AUTOSAR XML (schema 4-2-2)
package /STELLANTIS/EPT/ASWCs
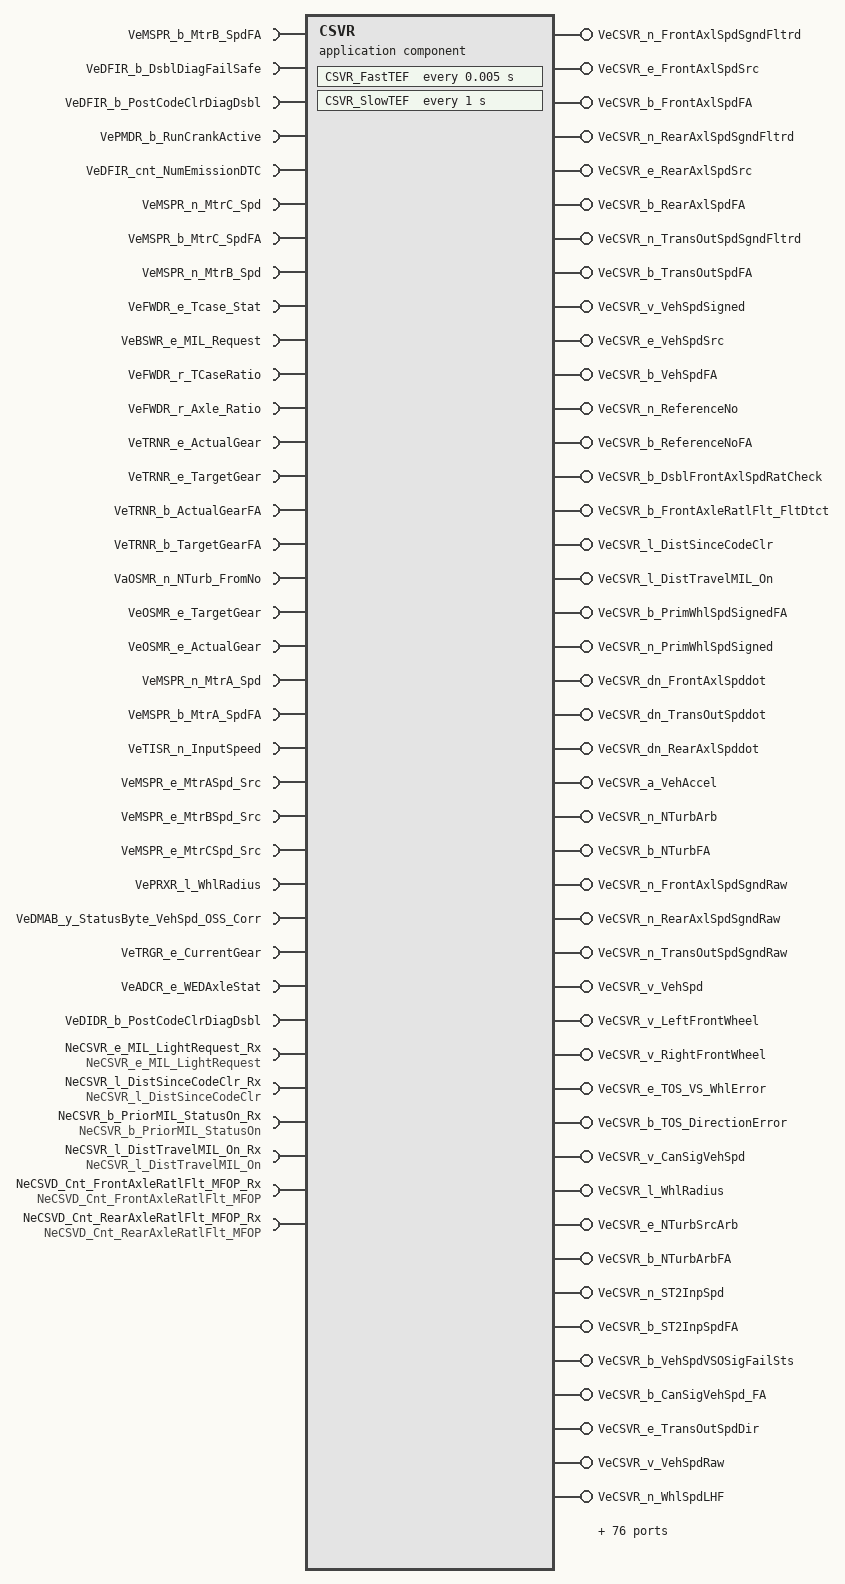
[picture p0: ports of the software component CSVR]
  application sw component type CSVR
    30 x require port:
      VeMSPR_b_MtrB_SpdFA: nonqueued-receiver-com-spec{data-element=Value, init-value=0}, required-interface=VeMSPR_b_MtrB_SpdFA
      VeDFIR_b_DsblDiagFailSafe: nonqueued-receiver-com-spec{data-element=Value, init-value=0}, required-interface=VeDFIR_b_DsblDiagFailSafe
      VeDFIR_b_PostCodeClrDiagDsbl: nonqueued-receiver-com-spec{data-element=Value, init-value=0}, required-interface=VeDFIR_b_PostCodeClrDiagDsbl
      VePMDR_b_RunCrankActive: nonqueued-receiver-com-spec{data-element=Value, init-value=0}, required-interface=VePMDR_b_RunCrankActive
      VeDFIR_cnt_NumEmissionDTC: nonqueued-receiver-com-spec{data-element=Value, init-value=0}, required-interface=VeDFIR_cnt_NumEmissionDTC
      VeMSPR_n_MtrC_Spd: nonqueued-receiver-com-spec{data-element=Value, init-value=0}, required-interface=VeMSPR_n_MtrC_Spd
      VeMSPR_b_MtrC_SpdFA: nonqueued-receiver-com-spec{data-element=Value, init-value=0}, required-interface=VeMSPR_b_MtrC_SpdFA
      VeMSPR_n_MtrB_Spd: nonqueued-receiver-com-spec{data-element=Value, init-value=0}, required-interface=VeMSPR_n_MtrB_Spd
      VeFWDR_e_Tcase_Stat: nonqueued-receiver-com-spec{data-element=Value, init-value=CeFWDR_e_ShiftINProg}, required-interface=VeFWDR_e_Tcase_Stat
      VeBSWR_e_MIL_Request: nonqueued-receiver-com-spec{data-element=Value, init-value=CeDFIR_MIL_Off}, required-interface=VeBSWR_e_MIL_Request
      VeFWDR_r_TCaseRatio: nonqueued-receiver-com-spec{data-element=Value, init-value=0}, required-interface=VeFWDR_r_TCaseRatio
      VeFWDR_r_Axle_Ratio: nonqueued-receiver-com-spec{data-element=Value, init-value=0}, required-interface=VeFWDR_r_Axle_Ratio
      VeTRNR_e_ActualGear: nonqueued-receiver-com-spec{data-element=Value, init-value=CeTRNR_e_Neutral}, required-interface=VeTRNR_e_ActualGear
      VeTRNR_e_TargetGear: nonqueued-receiver-com-spec{data-element=Value, init-value=CeTRNR_e_Neutral}, required-interface=VeTRNR_e_TargetGear
      VeTRNR_b_ActualGearFA: nonqueued-receiver-com-spec{data-element=Value, init-value=0}, required-interface=VeTRNR_b_ActualGearFA
      VeTRNR_b_TargetGearFA: nonqueued-receiver-com-spec{data-element=Value, init-value=0}, required-interface=VeTRNR_b_TargetGearFA
      VaOSMR_n_NTurb_FromNo: nonqueued-receiver-com-spec{data-element=Value, init-value=9 x 0}, required-interface=VaOSMR_n_NTurb_FromNo
      VeOSMR_e_TargetGear: nonqueued-receiver-com-spec{data-element=Value, init-value=CeTRNR_e_Neutral}, required-interface=VeOSMR_e_TargetGear
      VeOSMR_e_ActualGear: nonqueued-receiver-com-spec{data-element=Value, init-value=CeTRNR_e_Neutral}, required-interface=VeOSMR_e_ActualGear
      VeMSPR_n_MtrA_Spd: nonqueued-receiver-com-spec{data-element=Value, init-value=0}, required-interface=VeMSPR_n_MtrA_Spd
      VeMSPR_b_MtrA_SpdFA: nonqueued-receiver-com-spec{data-element=Value, init-value=0}, required-interface=VeMSPR_b_MtrA_SpdFA
      VeTISR_n_InputSpeed: nonqueued-receiver-com-spec{data-element=Value, init-value=0}, required-interface=VeTISR_n_InputSpeed
      VeMSPR_e_MtrASpd_Src: nonqueued-receiver-com-spec{data-element=Value, init-value=CeMSPR_e_MtrSpSrc_MCP}, required-interface=VeMSPR_e_MtrASpd_Src
      VeMSPR_e_MtrBSpd_Src: nonqueued-receiver-com-spec{data-element=Value, init-value=CeMSPR_e_MtrSpSrc_MCP}, required-interface=VeMSPR_e_MtrBSpd_Src
      VeMSPR_e_MtrCSpd_Src: nonqueued-receiver-com-spec{data-element=Value, init-value=CeMSPR_e_MtrSpSrc_MCP}, required-interface=VeMSPR_e_MtrCSpd_Src
      VePRXR_l_WhlRadius: nonqueued-receiver-com-spec{data-element=Value, init-value=0}, required-interface=VePRXR_l_WhlRadius
      VeDMAB_y_StatusByte_VehSpd_OSS_Corr: nonqueued-receiver-com-spec{data-element=Value, init-value=0}, required-interface=VeDMAB_y_StatusByte_VehSpd_OSS_Corr
      VeTRGR_e_CurrentGear: nonqueued-receiver-com-spec{data-element=Value, init-value=0}, required-interface=VeTRGR_e_CurrentGear
      VeADCR_e_WEDAxleStat: nonqueued-receiver-com-spec{data-element=Value, init-value=CeADCR_e_Init}, required-interface=VeADCR_e_WEDAxleStat
      VeDIDR_b_PostCodeClrDiagDsbl: nonqueued-receiver-com-spec{data-element=VeDIDR_b_PostCodeClrDiagDsbl, init-value=0}, required-interface=VeDIDR_b_PostCodeClrDiagDsbl
    114 x provide port:
      VeCSVR_n_FrontAxlSpdSgndFltrd: nonqueued-sender-com-spec{data-element=Value, init-value=0}, provided-interface=VeCSVR_n_FrontAxlSpdSgndFltrd
      VeCSVR_e_FrontAxlSpdSrc: nonqueued-sender-com-spec{data-element=Value, init-value=CeCSVR_e_NoValidFASSrcAvail}, provided-interface=VeCSVR_e_FrontAxlSpdSrc
      VeCSVR_b_FrontAxlSpdFA: nonqueued-sender-com-spec{data-element=Value, init-value=0}, provided-interface=VeCSVR_b_FrontAxlSpdFA
      VeCSVR_n_RearAxlSpdSgndFltrd: nonqueued-sender-com-spec{data-element=Value, init-value=0}, provided-interface=VeCSVR_n_RearAxlSpdSgndFltrd
      VeCSVR_e_RearAxlSpdSrc: nonqueued-sender-com-spec{data-element=Value, init-value=CeCSVR_e_NoValidRASSrcAvail}, provided-interface=VeCSVR_e_RearAxlSpdSrc
      VeCSVR_b_RearAxlSpdFA: nonqueued-sender-com-spec{data-element=Value, init-value=0}, provided-interface=VeCSVR_b_RearAxlSpdFA
      VeCSVR_n_TransOutSpdSgndFltrd: nonqueued-sender-com-spec{data-element=Value, init-value=0}, provided-interface=VeCSVR_n_TransOutSpdSgndFltrd
      VeCSVR_b_TransOutSpdFA: nonqueued-sender-com-spec{data-element=Value, init-value=0}, provided-interface=VeCSVR_b_TransOutSpdFA
      VeCSVR_v_VehSpdSigned: nonqueued-sender-com-spec{data-element=Value, init-value=0}, provided-interface=VeCSVR_v_VehSpdSigned
      VeCSVR_e_VehSpdSrc: nonqueued-sender-com-spec{data-element=Value, init-value=CeCSVR_e_VehSpdFrmCAN}, provided-interface=VeCSVR_e_VehSpdSrc
      VeCSVR_b_VehSpdFA: nonqueued-sender-com-spec{data-element=Value, init-value=0}, provided-interface=VeCSVR_b_VehSpdFA
      VeCSVR_n_ReferenceNo: nonqueued-sender-com-spec{data-element=Value, init-value=0}, provided-interface=VeCSVR_n_ReferenceNo
      VeCSVR_b_ReferenceNoFA: nonqueued-sender-com-spec{data-element=Value, init-value=0}, provided-interface=VeCSVR_b_ReferenceNoFA
      VeCSVR_b_DsblFrontAxlSpdRatCheck: nonqueued-sender-com-spec{data-element=Value, init-value=0}, provided-interface=VeCSVR_b_DsblFrontAxlSpdRatCheck
      VeCSVR_b_FrontAxleRatlFlt_FltDtct: nonqueued-sender-com-spec{data-element=Value, init-value=0}, provided-interface=VeCSVR_b_FrontAxleRatlFlt_FltDtct
      VeCSVR_l_DistSinceCodeClr: nonqueued-sender-com-spec{data-element=Value, init-value=0}, provided-interface=VeCSVR_l_DistSinceCodeClr
      VeCSVR_l_DistTravelMIL_On: nonqueued-sender-com-spec{data-element=Value, init-value=0}, provided-interface=VeCSVR_l_DistTravelMIL_On
      VeCSVR_b_PrimWhlSpdSignedFA: nonqueued-sender-com-spec{data-element=Value, init-value=0}, provided-interface=VeCSVR_b_PrimWhlSpdSignedFA
      VeCSVR_n_PrimWhlSpdSigned: nonqueued-sender-com-spec{data-element=Value, init-value=0}, provided-interface=VeCSVR_n_PrimWhlSpdSigned
      VeCSVR_dn_FrontAxlSpddot: nonqueued-sender-com-spec{data-element=Value, init-value=0}, provided-interface=VeCSVR_dn_FrontAxlSpddot
      VeCSVR_dn_TransOutSpddot: nonqueued-sender-com-spec{data-element=Value, init-value=0}, provided-interface=VeCSVR_dn_TransOutSpddot
      VeCSVR_dn_RearAxlSpddot: nonqueued-sender-com-spec{data-element=Value, init-value=0}, provided-interface=VeCSVR_dn_RearAxlSpddot
      VeCSVR_a_VehAccel: nonqueued-sender-com-spec{data-element=Value, init-value=0}, provided-interface=VeCSVR_a_VehAccel
      VeCSVR_n_NTurbArb: nonqueued-sender-com-spec{data-element=Value, init-value=0}, provided-interface=VeCSVR_n_NTurbArb
      VeCSVR_b_NTurbFA: nonqueued-sender-com-spec{data-element=Value, init-value=0}, provided-interface=VeCSVR_b_NTurbFA
      VeCSVR_n_FrontAxlSpdSgndRaw: nonqueued-sender-com-spec{data-element=Value, init-value=0}, provided-interface=VeCSVR_n_FrontAxlSpdSgndRaw
      VeCSVR_n_RearAxlSpdSgndRaw: nonqueued-sender-com-spec{data-element=Value, init-value=0}, provided-interface=VeCSVR_n_RearAxlSpdSgndRaw
      VeCSVR_n_TransOutSpdSgndRaw: nonqueued-sender-com-spec{data-element=Value, init-value=0}, provided-interface=VeCSVR_n_TransOutSpdSgndRaw
      VeCSVR_v_VehSpd: nonqueued-sender-com-spec{data-element=Value, init-value=0}, provided-interface=VeCSVR_v_VehSpd
      VeCSVR_v_LeftFrontWheel: nonqueued-sender-com-spec{data-element=Value, init-value=0}, provided-interface=VeCSVR_v_LeftFrontWheel
      VeCSVR_v_RightFrontWheel: nonqueued-sender-com-spec{data-element=Value, init-value=0}, provided-interface=VeCSVR_v_RightFrontWheel
      VeCSVR_e_TOS_VS_WhlError: nonqueued-sender-com-spec{data-element=Value, init-value=CeCSVR_e_TOS_VS_WhlUnknown}, provided-interface=VeCSVR_e_TOS_VS_WhlError
      VeCSVR_b_TOS_DirectionError: nonqueued-sender-com-spec{data-element=Value, init-value=0}, provided-interface=VeCSVR_b_TOS_DirectionError
      VeCSVR_v_CanSigVehSpd: nonqueued-sender-com-spec{data-element=Value, init-value=0}, provided-interface=VeCSVR_v_CanSigVehSpd
      VeCSVR_l_WhlRadius: nonqueued-sender-com-spec{data-element=Value, init-value=0}, provided-interface=VeCSVR_l_WhlRadius
      VeCSVR_e_NTurbSrcArb: nonqueued-sender-com-spec{data-element=Value, init-value=CeCSVR_e_NturbFromCAN}, provided-interface=VeCSVR_e_NTurbSrcArb
      VeCSVR_b_NTurbArbFA: nonqueued-sender-com-spec{data-element=Value, init-value=0}, provided-interface=VeCSVR_b_NTurbArbFA
      VeCSVR_n_ST2InpSpd: nonqueued-sender-com-spec{data-element=Value, init-value=0}, provided-interface=VeCSVR_n_ST2InpSpd
      VeCSVR_b_ST2InpSpdFA: nonqueued-sender-com-spec{data-element=Value, init-value=0}, provided-interface=VeCSVR_b_ST2InpSpdFA
      VeCSVR_b_VehSpdVSOSigFailSts: nonqueued-sender-com-spec{data-element=Value, init-value=0}, provided-interface=VeCSVR_b_VehSpdVSOSigFailSts
      VeCSVR_b_CanSigVehSpd_FA: nonqueued-sender-com-spec{data-element=Value, init-value=0}, provided-interface=VeCSVR_b_CanSigVehSpd_FA
      VeCSVR_e_TransOutSpdDir: nonqueued-sender-com-spec{data-element=Value, init-value=CeCSVR_e_WheelDirectionUnknown}, provided-interface=VeCSVR_e_TransOutSpdDir
      VeCSVR_v_VehSpdRaw: nonqueued-sender-com-spec{data-element=Value, init-value=0}, provided-interface=VeCSVR_v_VehSpdRaw
      VeCSVR_n_WhlSpdLHF: nonqueued-sender-com-spec{data-element=Value, init-value=0}, provided-interface=VeCSVR_n_WhlSpdLHF
      VeCSVR_n_WhlSpdLHR: nonqueued-sender-com-spec{data-element=Value, init-value=0}, provided-interface=VeCSVR_n_WhlSpdLHR
      VeCSVR_n_WhlSpdRHF: nonqueued-sender-com-spec{data-element=Value, init-value=0}, provided-interface=VeCSVR_n_WhlSpdRHF
      VeCSVR_n_WhlSpdRHR: nonqueued-sender-com-spec{data-element=Value, init-value=0}, provided-interface=VeCSVR_n_WhlSpdRHR
      VeCSVR_b_WhlSpdLHF_FA: nonqueued-sender-com-spec{data-element=Value, init-value=0}, provided-interface=VeCSVR_b_WhlSpdLHF_FA
      VeCSVR_b_WhlSpdLHR_FA: nonqueued-sender-com-spec{data-element=Value, init-value=0}, provided-interface=VeCSVR_b_WhlSpdLHR_FA
      VeCSVR_b_WhlSpdRHF_FA: nonqueued-sender-com-spec{data-element=Value, init-value=0}, provided-interface=VeCSVR_b_WhlSpdRHF_FA
      VeCSVR_b_WhlSpdRHR_FA: nonqueued-sender-com-spec{data-element=Value, init-value=0}, provided-interface=VeCSVR_b_WhlSpdRHR_FA
      VeCSVR_b_WheelSensorFailStsLHF: nonqueued-sender-com-spec{data-element=Value, init-value=0}, provided-interface=VeCSVR_b_WheelSensorFailStsLHF
      VeCSVR_b_WheelSensorFailStsLHR: nonqueued-sender-com-spec{data-element=Value, init-value=0}, provided-interface=VeCSVR_b_WheelSensorFailStsLHR
      VeCSVR_b_WheelSensorFailStsRHF: nonqueued-sender-com-spec{data-element=Value, init-value=0}, provided-interface=VeCSVR_b_WheelSensorFailStsRHF
      VeCSVR_b_WheelSensorFailStsRHR: nonqueued-sender-com-spec{data-element=Value, init-value=0}, provided-interface=VeCSVR_b_WheelSensorFailStsRHR
      VeCSVR_e_FrontAxlDir: nonqueued-sender-com-spec{data-element=Value, init-value=CeCSVR_e_WheelDirectionUnknown}, provided-interface=VeCSVR_e_FrontAxlDir
      VeCSVR_e_RearAxlDir: nonqueued-sender-com-spec{data-element=Value, init-value=CeCSVR_e_WheelDirectionUnknown}, provided-interface=VeCSVR_e_RearAxlDir
      VeCSVR_v_LeftRearWheel: nonqueued-sender-com-spec{data-element=Value, init-value=0}, provided-interface=VeCSVR_v_LeftRearWheel
      VeCSVR_v_RightRearWheel: nonqueued-sender-com-spec{data-element=Value, init-value=0}, provided-interface=VeCSVR_v_RightRearWheel
      VeCSVR_e_FrontLeftWhlDir: nonqueued-sender-com-spec{data-element=Value, init-value=CeCSVR_e_WheelDirectionUnknown}, provided-interface=VeCSVR_e_FrontLeftWhlDir
      VeCSVR_e_RearLeftWhlDir: nonqueued-sender-com-spec{data-element=Value, init-value=CeCSVR_e_WheelDirectionUnknown}, provided-interface=VeCSVR_e_RearLeftWhlDir
      VeCSVR_e_FrontRightWhlDir: nonqueued-sender-com-spec{data-element=Value, init-value=CeCSVR_e_WheelDirectionUnknown}, provided-interface=VeCSVR_e_FrontRightWhlDir
      VeCSVR_e_RearRightWhlDir: nonqueued-sender-com-spec{data-element=Value, init-value=CeCSVR_e_WheelDirectionUnknown}, provided-interface=VeCSVR_e_RearRightWhlDir
      VeCSVR_b_SecWhlSpdSignedFA: nonqueued-sender-com-spec{data-element=Value, init-value=0}, provided-interface=VeCSVR_b_SecWhlSpdSignedFA
      VeCSVR_n_SecWhlSpdSigned: nonqueued-sender-com-spec{data-element=Value, init-value=0}, provided-interface=VeCSVR_n_SecWhlSpdSigned
      VeCSVR_e_FaultSts_VehSpd_OSS_Corr: nonqueued-sender-com-spec{data-element=Value, init-value=CeDFIB_e_Init}, provided-interface=VeCSVR_e_FaultSts_VehSpd_OSS_Corr
      VeCSVR_e_THA_RespEVCU2: nonqueued-sender-com-spec{data-element=Value, init-value=CeCSVR_e_THAr_Off}, provided-interface=VeCSVR_e_THA_RespEVCU2
      VeCSVR_e_TRSC_RespEVCU2: nonqueued-sender-com-spec{data-element=Value, init-value=CeCSVR_e_TRSCr_Off}, provided-interface=VeCSVR_e_TRSC_RespEVCU2
      VeCSVR_e_THA_SpdLimInt: nonqueued-sender-com-spec{data-element=Value, init-value=CeCSVR_e_THAsl_NoRequest}, provided-interface=VeCSVR_e_THA_SpdLimInt
      VeCSVR_e_TRSC_SpdLimReqInt: nonqueued-sender-com-spec{data-element=Value, init-value=CeCSVR_e_TRSCslr_NotLimiting}, provided-interface=VeCSVR_e_TRSC_SpdLimReqInt
      FsftCSVR_b_THA_STAT: server-com-spec=FsftCSVR_b_THA_STAT, provided-interface=FsftCSVR_b_THA_STAT
      FsftCSVR_b_THA_SpdLim: server-com-spec=FsftCSVR_b_THA_SpdLim, provided-interface=FsftCSVR_b_THA_SpdLim
      FsftCSVR_b_TRSC_STAT: server-com-spec=FsftCSVR_b_TRSC_STAT, provided-interface=FsftCSVR_b_TRSC_STAT
      FsftCSVR_b_TRSC_SpdLimReq: server-com-spec=FsftCSVR_b_TRSC_SpdLimReq, provided-interface=FsftCSVR_b_TRSC_SpdLimReq
      FsftCSVR_e_LeftFrontWhlDir: server-com-spec=FsftCSVR_e_LeftFrontWhlDir, provided-interface=FsftCSVR_e_LeftFrontWhlDir
      FsftCSVR_e_LeftRearWhlDir: server-com-spec=FsftCSVR_e_LeftRearWhlDir, provided-interface=FsftCSVR_e_LeftRearWhlDir
      FsftCSVR_e_OutSpdPolarity: server-com-spec=FsftCSVR_e_OutSpdPolarity, provided-interface=FsftCSVR_e_OutSpdPolarity
      FsftCSVR_e_RightFrontWhlDir: server-com-spec=FsftCSVR_e_RightFrontWhlDir, provided-interface=FsftCSVR_e_RightFrontWhlDir
      FsftCSVR_e_RightRearWhlDir: server-com-spec=FsftCSVR_e_RightRearWhlDir, provided-interface=FsftCSVR_e_RightRearWhlDir
      FsftCSVR_n_LeftFrontWhl: server-com-spec=FsftCSVR_n_LeftFrontWhl, provided-interface=FsftCSVR_n_LeftFrontWhl
      FsftCSVR_n_LeftRearWhl: server-com-spec=FsftCSVR_n_LeftRearWhl, provided-interface=FsftCSVR_n_LeftRearWhl
      FsftCSVR_n_Nturb: server-com-spec=FsftCSVR_n_Nturb, provided-interface=FsftCSVR_n_Nturb
      FsftCSVR_n_RightFrontWhl: server-com-spec=FsftCSVR_n_RightFrontWhl, provided-interface=FsftCSVR_n_RightFrontWhl
      FsftCSVR_n_RightRearWhl: server-com-spec=FsftCSVR_n_RightRearWhl, provided-interface=FsftCSVR_n_RightRearWhl
      FsftCSVR_n_ST2InpSpd: server-com-spec=FsftCSVR_n_ST2InpSpd, provided-interface=FsftCSVR_n_ST2InpSpd
      FsftCSVR_n_TOSSnsrSpdRaw: server-com-spec=FsftCSVR_n_TOSSnsrSpdRaw, provided-interface=FsftCSVR_n_TOSSnsrSpdRaw
      FsftCSVR_v_CanSigVehSpd: server-com-spec=FsftCSVR_v_CanSigVehSpd, provided-interface=FsftCSVR_v_CanSigVehSpd
      FsftCSVR_v_CanSigVehSpd_CANC2: server-com-spec=FsftCSVR_v_CanSigVehSpd_CANC2, provided-interface=FsftCSVR_v_CanSigVehSpd_CANC2
      FsftCSVR_v_RefVehSpd: server-com-spec=FsftCSVR_v_RefVehSpd, provided-interface=FsftCSVR_v_RefVehSpd
      PokeCSVR_b_VehSpdVSOSigFailSts: server-com-spec{operation=PokeCSVR_b_VehSpdVSOSigFailSts, queue-length=1}, provided-interface=PokeCSVR_b_VehSpdVSOSigFailSts
      PokeCSVR_b_VehSpdVSOSigFailSts_CANC2: server-com-spec{operation=PokeCSVR_b_VehSpdVSOSigFailSts_CANC2, queue-length=1}, provided-interface=PokeCSVR_b_VehSpdVSOSigFailSts_CANC2
      PokeCSVR_b_WheelSensorFailStsLHF: server-com-spec{operation=PokeCSVR_b_WheelSensorFailStsLHF, queue-length=1}, provided-interface=PokeCSVR_b_WheelSensorFailStsLHF
      PokeCSVR_b_WheelSensorFailStsLHR: server-com-spec{operation=PokeCSVR_b_WheelSensorFailStsLHR, queue-length=1}, provided-interface=PokeCSVR_b_WheelSensorFailStsLHR
      PokeCSVR_b_WheelSensorFailStsRHF: server-com-spec{operation=PokeCSVR_b_WheelSensorFailStsRHF, queue-length=1}, provided-interface=PokeCSVR_b_WheelSensorFailStsRHF
      PokeCSVR_b_WheelSensorFailStsRHR: server-com-spec{operation=PokeCSVR_b_WheelSensorFailStsRHR, queue-length=1}, provided-interface=PokeCSVR_b_WheelSensorFailStsRHR
      PokeCSVR_e_LeftFrontWhlDir: server-com-spec{operation=PokeCSVR_e_LeftFrontWhlDir, queue-length=1}, provided-interface=PokeCSVR_e_LeftFrontWhlDir
      PokeCSVR_e_LeftRearWhlDir: server-com-spec{operation=PokeCSVR_e_LeftRearWhlDir, queue-length=1}, provided-interface=PokeCSVR_e_LeftRearWhlDir
      PokeCSVR_e_OutSpdPolarity: server-com-spec{operation=PokeCSVR_e_OutSpdPolarity, queue-length=1}, provided-interface=PokeCSVR_e_OutSpdPolarity
      PokeCSVR_e_RightFrontWhlDir: server-com-spec{operation=PokeCSVR_e_RightFrontWhlDir, queue-length=1}, provided-interface=PokeCSVR_e_RightFrontWhlDir
      PokeCSVR_e_RightRearWhlDir: server-com-spec{operation=PokeCSVR_e_RightRearWhlDir, queue-length=1}, provided-interface=PokeCSVR_e_RightRearWhlDir
      PokeCSVR_e_THA_STAT: server-com-spec{operation=PokeCSVR_e_THA_STAT, queue-length=1}, provided-interface=PokeCSVR_e_THA_STAT
      PokeCSVR_e_THA_SpdLim: server-com-spec{operation=PokeCSVR_e_THA_SpdLim, queue-length=1}, provided-interface=PokeCSVR_e_THA_SpdLim
      PokeCSVR_e_TRSC_STAT: server-com-spec{operation=PokeCSVR_e_TRSC_STAT, queue-length=1}, provided-interface=PokeCSVR_e_TRSC_STAT
      PokeCSVR_e_TRSC_SpdLimReq: server-com-spec{operation=PokeCSVR_e_TRSC_SpdLimReq, queue-length=1}, provided-interface=PokeCSVR_e_TRSC_SpdLimReq
      PokeCSVR_n_LeftFrontWhl: server-com-spec{operation=PokeCSVR_n_LeftFrontWhl, queue-length=1}, provided-interface=PokeCSVR_n_LeftFrontWhl
      PokeCSVR_n_LeftRearWhl: server-com-spec{operation=PokeCSVR_n_LeftRearWhl, queue-length=1}, provided-interface=PokeCSVR_n_LeftRearWhl
      PokeCSVR_n_Nturb: server-com-spec{operation=PokeCSVR_n_Nturb, queue-length=1}, provided-interface=PokeCSVR_n_Nturb
      PokeCSVR_n_RightFrontWhl: server-com-spec{operation=PokeCSVR_n_RightFrontWhl, queue-length=1}, provided-interface=PokeCSVR_n_RightFrontWhl
      PokeCSVR_n_RightRearWhl: server-com-spec{operation=PokeCSVR_n_RightRearWhl, queue-length=1}, provided-interface=PokeCSVR_n_RightRearWhl
      PokeCSVR_n_ST2InpSpd: server-com-spec{operation=PokeCSVR_n_ST2InpSpd, queue-length=1}, provided-interface=PokeCSVR_n_ST2InpSpd
      PokeCSVR_n_TOSSnsrSpdRaw: server-com-spec{operation=PokeCSVR_n_TOSSnsrSpdRaw, queue-length=1}, provided-interface=PokeCSVR_n_TOSSnsrSpdRaw
      PokeCSVR_v_CanSigVehSpd: server-com-spec{operation=PokeCSVR_v_CanSigVehSpd, queue-length=1}, provided-interface=PokeCSVR_v_CanSigVehSpd
      PokeCSVR_v_CanSigVehSpd_CANC2: server-com-spec{operation=PokeCSVR_v_CanSigVehSpd_CANC2, queue-length=1}, provided-interface=PokeCSVR_v_CanSigVehSpd_CANC2
      PokeCSVR_v_RefVehSpd: server-com-spec{operation=PokeCSVR_v_RefVehSpd, queue-length=1}, provided-interface=PokeCSVR_v_RefVehSpd
    6 x require port:
      NeCSVR_e_MIL_LightRequest_Rx: nv-require-com-spec{init-value=CeDFIR_MIL_Off, variable=NeCSVR_e_MIL_LightRequest}, required-interface=NeCSVR_e_MIL_LightRequest
      NeCSVR_l_DistSinceCodeClr_Rx: nv-require-com-spec{init-value=0, variable=NeCSVR_l_DistSinceCodeClr}, required-interface=NeCSVR_l_DistSinceCodeClr
      NeCSVR_b_PriorMIL_StatusOn_Rx: nv-require-com-spec{init-value=0, variable=NeCSVR_b_PriorMIL_StatusOn}, required-interface=NeCSVR_b_PriorMIL_StatusOn
      NeCSVR_l_DistTravelMIL_On_Rx: nv-require-com-spec{init-value=0, variable=NeCSVR_l_DistTravelMIL_On}, required-interface=NeCSVR_l_DistTravelMIL_On
      NeCSVD_Cnt_FrontAxleRatlFlt_MFOP_Rx: nv-require-com-spec{init-value=0, variable=NeCSVD_Cnt_FrontAxleRatlFlt_MFOP}, required-interface=NeCSVD_Cnt_FrontAxleRatlFlt_MFOP
      NeCSVD_Cnt_RearAxleRatlFlt_MFOP_Rx: nv-require-com-spec{init-value=0, variable=NeCSVD_Cnt_RearAxleRatlFlt_MFOP}, required-interface=NeCSVD_Cnt_RearAxleRatlFlt_MFOP
    6 x provide port:
      NeCSVR_e_MIL_LightRequest: nv-provide-com-spec{ram-block-init-value=CeDFIR_MIL_Off, variable=NeCSVR_e_MIL_LightRequest}, provided-interface=NeCSVR_e_MIL_LightRequest
      NeCSVR_l_DistSinceCodeClr: nv-provide-com-spec{ram-block-init-value=0, variable=NeCSVR_l_DistSinceCodeClr}, provided-interface=NeCSVR_l_DistSinceCodeClr
      NeCSVR_b_PriorMIL_StatusOn: nv-provide-com-spec{ram-block-init-value=0, variable=NeCSVR_b_PriorMIL_StatusOn}, provided-interface=NeCSVR_b_PriorMIL_StatusOn
      NeCSVR_l_DistTravelMIL_On: nv-provide-com-spec{ram-block-init-value=0, variable=NeCSVR_l_DistTravelMIL_On}, provided-interface=NeCSVR_l_DistTravelMIL_On
      NeCSVD_Cnt_FrontAxleRatlFlt_MFOP: nv-provide-com-spec{ram-block-init-value=0, variable=NeCSVD_Cnt_FrontAxleRatlFlt_MFOP}, provided-interface=NeCSVD_Cnt_FrontAxleRatlFlt_MFOP
      NeCSVD_Cnt_RearAxleRatlFlt_MFOP: nv-provide-com-spec{ram-block-init-value=0, variable=NeCSVD_Cnt_RearAxleRatlFlt_MFOP}, provided-interface=NeCSVD_Cnt_RearAxleRatlFlt_MFOP
    behavior IB_CSVR: data-type-mapping=msADTtoIDTMapping, handle-termination-and-restart=NO-SUPPORT, included-data-type-set=data-type=[TeCSVR_e_RefSpdSrc, TeCSVR_e_TransOutSpdSrc]
      timing event Event_FastTEF: start-on-event=CSVR_FastTEF, period=0.005
      timing event Event_SlowTEF: start-on-event=CSVR_SlowTEF, period=1
      44 x operation invoked event:
        Event_FsftCSVR_b_THA_STAT: start-on-event=FsftCSVR_b_THA_STAT, operation=FsftCSVR_b_THA_STAT.FsftCSVR_b_THA_STAT
        Event_FsftCSVR_b_THA_SpdLim: start-on-event=FsftCSVR_b_THA_SpdLim, operation=FsftCSVR_b_THA_SpdLim.FsftCSVR_b_THA_SpdLim
        Event_FsftCSVR_b_TRSC_STAT: start-on-event=FsftCSVR_b_TRSC_STAT, operation=FsftCSVR_b_TRSC_STAT.FsftCSVR_b_TRSC_STAT
        Event_FsftCSVR_b_TRSC_SpdLimReq: start-on-event=FsftCSVR_b_TRSC_SpdLimReq, operation=FsftCSVR_b_TRSC_SpdLimReq.FsftCSVR_b_TRSC_SpdLimReq
        Event_FsftCSVR_e_LeftFrontWhlDir: start-on-event=FsftCSVR_e_LeftFrontWhlDir, operation=FsftCSVR_e_LeftFrontWhlDir.FsftCSVR_e_LeftFrontWhlDir
        Event_FsftCSVR_e_LeftRearWhlDir: start-on-event=FsftCSVR_e_LeftRearWhlDir, operation=FsftCSVR_e_LeftRearWhlDir.FsftCSVR_e_LeftRearWhlDir
        Event_FsftCSVR_e_OutSpdPolarity: start-on-event=FsftCSVR_e_OutSpdPolarity, operation=FsftCSVR_e_OutSpdPolarity.FsftCSVR_e_OutSpdPolarity
        Event_FsftCSVR_e_RightFrontWhlDir: start-on-event=FsftCSVR_e_RightFrontWhlDir, operation=FsftCSVR_e_RightFrontWhlDir.FsftCSVR_e_RightFrontWhlDir
        Event_FsftCSVR_e_RightRearWhlDir: start-on-event=FsftCSVR_e_RightRearWhlDir, operation=FsftCSVR_e_RightRearWhlDir.FsftCSVR_e_RightRearWhlDir
        Event_FsftCSVR_n_LeftFrontWhl: start-on-event=FsftCSVR_n_LeftFrontWhl, operation=FsftCSVR_n_LeftFrontWhl.FsftCSVR_n_LeftFrontWhl
        Event_FsftCSVR_n_LeftRearWhl: start-on-event=FsftCSVR_n_LeftRearWhl, operation=FsftCSVR_n_LeftRearWhl.FsftCSVR_n_LeftRearWhl
        Event_FsftCSVR_n_Nturb: start-on-event=FsftCSVR_n_Nturb, operation=FsftCSVR_n_Nturb.FsftCSVR_n_Nturb
        Event_FsftCSVR_n_RightFrontWhl: start-on-event=FsftCSVR_n_RightFrontWhl, operation=FsftCSVR_n_RightFrontWhl.FsftCSVR_n_RightFrontWhl
        Event_FsftCSVR_n_RightRearWhl: start-on-event=FsftCSVR_n_RightRearWhl, operation=FsftCSVR_n_RightRearWhl.FsftCSVR_n_RightRearWhl
        Event_FsftCSVR_n_ST2InpSpd: start-on-event=FsftCSVR_n_ST2InpSpd, operation=FsftCSVR_n_ST2InpSpd.FsftCSVR_n_ST2InpSpd
        Event_FsftCSVR_n_TOSSnsrSpdRaw: start-on-event=FsftCSVR_n_TOSSnsrSpdRaw, operation=FsftCSVR_n_TOSSnsrSpdRaw.FsftCSVR_n_TOSSnsrSpdRaw
        Event_FsftCSVR_v_CanSigVehSpd: start-on-event=FsftCSVR_v_CanSigVehSpd, operation=FsftCSVR_v_CanSigVehSpd.FsftCSVR_v_CanSigVehSpd
        Event_FsftCSVR_v_CanSigVehSpd_CANC2: start-on-event=FsftCSVR_v_CanSigVehSpd_CANC2, operation=FsftCSVR_v_CanSigVehSpd_CANC2.FsftCSVR_v_CanSigVehSpd_CANC2
        Event_FsftCSVR_v_RefVehSpd: start-on-event=FsftCSVR_v_RefVehSpd, operation=FsftCSVR_v_RefVehSpd.FsftCSVR_v_RefVehSpd
        Event_PokeCSVR_b_VehSpdVSOSigFailSts: start-on-event=PokeCSVR_b_VehSpdVSOSigFailSts, operation=PokeCSVR_b_VehSpdVSOSigFailSts.PokeCSVR_b_VehSpdVSOSigFailSts
        Event_PokeCSVR_b_VehSpdVSOSigFailSts_CANC2: start-on-event=PokeCSVR_b_VehSpdVSOSigFailSts_CANC2, operation=PokeCSVR_b_VehSpdVSOSigFailSts_CANC2.PokeCSVR_b_VehSpdVSOSigFailSts_CANC2
        Event_PokeCSVR_b_WheelSensorFailStsLHF: start-on-event=PokeCSVR_b_WheelSensorFailStsLHF, operation=PokeCSVR_b_WheelSensorFailStsLHF.PokeCSVR_b_WheelSensorFailStsLHF
        Event_PokeCSVR_b_WheelSensorFailStsLHR: start-on-event=PokeCSVR_b_WheelSensorFailStsLHR, operation=PokeCSVR_b_WheelSensorFailStsLHR.PokeCSVR_b_WheelSensorFailStsLHR
        Event_PokeCSVR_b_WheelSensorFailStsRHF: start-on-event=PokeCSVR_b_WheelSensorFailStsRHF, operation=PokeCSVR_b_WheelSensorFailStsRHF.PokeCSVR_b_WheelSensorFailStsRHF
        Event_PokeCSVR_b_WheelSensorFailStsRHR: start-on-event=PokeCSVR_b_WheelSensorFailStsRHR, operation=PokeCSVR_b_WheelSensorFailStsRHR.PokeCSVR_b_WheelSensorFailStsRHR
        Event_PokeCSVR_e_LeftFrontWhlDir: start-on-event=PokeCSVR_e_LeftFrontWhlDir, operation=PokeCSVR_e_LeftFrontWhlDir.PokeCSVR_e_LeftFrontWhlDir
        Event_PokeCSVR_e_LeftRearWhlDir: start-on-event=PokeCSVR_e_LeftRearWhlDir, operation=PokeCSVR_e_LeftRearWhlDir.PokeCSVR_e_LeftRearWhlDir
        Event_PokeCSVR_e_OutSpdPolarity: start-on-event=PokeCSVR_e_OutSpdPolarity, operation=PokeCSVR_e_OutSpdPolarity.PokeCSVR_e_OutSpdPolarity
        Event_PokeCSVR_e_RightFrontWhlDir: start-on-event=PokeCSVR_e_RightFrontWhlDir, operation=PokeCSVR_e_RightFrontWhlDir.PokeCSVR_e_RightFrontWhlDir
        Event_PokeCSVR_e_RightRearWhlDir: start-on-event=PokeCSVR_e_RightRearWhlDir, operation=PokeCSVR_e_RightRearWhlDir.PokeCSVR_e_RightRearWhlDir
        Event_PokeCSVR_e_THA_STAT: start-on-event=PokeCSVR_e_THA_STAT, operation=PokeCSVR_e_THA_STAT.PokeCSVR_e_THA_STAT
        Event_PokeCSVR_e_THA_SpdLim: start-on-event=PokeCSVR_e_THA_SpdLim, operation=PokeCSVR_e_THA_SpdLim.PokeCSVR_e_THA_SpdLim
        Event_PokeCSVR_e_TRSC_STAT: start-on-event=PokeCSVR_e_TRSC_STAT, operation=PokeCSVR_e_TRSC_STAT.PokeCSVR_e_TRSC_STAT
        Event_PokeCSVR_e_TRSC_SpdLimReq: start-on-event=PokeCSVR_e_TRSC_SpdLimReq, operation=PokeCSVR_e_TRSC_SpdLimReq.PokeCSVR_e_TRSC_SpdLimReq
        Event_PokeCSVR_n_LeftFrontWhl: start-on-event=PokeCSVR_n_LeftFrontWhl, operation=PokeCSVR_n_LeftFrontWhl.PokeCSVR_n_LeftFrontWhl
        Event_PokeCSVR_n_LeftRearWhl: start-on-event=PokeCSVR_n_LeftRearWhl, operation=PokeCSVR_n_LeftRearWhl.PokeCSVR_n_LeftRearWhl
        Event_PokeCSVR_n_Nturb: start-on-event=PokeCSVR_n_Nturb, operation=PokeCSVR_n_Nturb.PokeCSVR_n_Nturb
        Event_PokeCSVR_n_RightFrontWhl: start-on-event=PokeCSVR_n_RightFrontWhl, operation=PokeCSVR_n_RightFrontWhl.PokeCSVR_n_RightFrontWhl
        Event_PokeCSVR_n_RightRearWhl: start-on-event=PokeCSVR_n_RightRearWhl, operation=PokeCSVR_n_RightRearWhl.PokeCSVR_n_RightRearWhl
        Event_PokeCSVR_n_ST2InpSpd: start-on-event=PokeCSVR_n_ST2InpSpd, operation=PokeCSVR_n_ST2InpSpd.PokeCSVR_n_ST2InpSpd
        Event_PokeCSVR_n_TOSSnsrSpdRaw: start-on-event=PokeCSVR_n_TOSSnsrSpdRaw, operation=PokeCSVR_n_TOSSnsrSpdRaw.PokeCSVR_n_TOSSnsrSpdRaw
        Event_PokeCSVR_v_CanSigVehSpd: start-on-event=PokeCSVR_v_CanSigVehSpd, operation=PokeCSVR_v_CanSigVehSpd.PokeCSVR_v_CanSigVehSpd
        Event_PokeCSVR_v_CanSigVehSpd_CANC2: start-on-event=PokeCSVR_v_CanSigVehSpd_CANC2, operation=PokeCSVR_v_CanSigVehSpd_CANC2.PokeCSVR_v_CanSigVehSpd_CANC2
        Event_PokeCSVR_v_RefVehSpd: start-on-event=PokeCSVR_v_RefVehSpd, operation=PokeCSVR_v_RefVehSpd.PokeCSVR_v_RefVehSpd
      init event Event_CSVR_ac_Init: start-on-event=CSVR_ac_Init
      data received event Event_ClearCodes_CSVR: start-on-event=ClearCodes_CSVR, data=VeDIDR_b_PostCodeClrDiagDsbl.VeDIDR_b_PostCodeClrDiagDsbl
      init event Event_PwrOn: start-on-event=CSVR_PwrOn
      init event Event_PwrOff: start-on-event=CSVR_PwrOff
      explicit-inter-runnable-variables:
        47 x data, all with category=VALUE, sw-calibration-access=READ-ONLY:
          Nturb_Init_write_IRV: type=Float, init-value=0
          NturbFA_Init_write_IRV: type=Boolean, init-value=0
          CanVehSpd_Init_write_IRV: type=Float, init-value=0
          CanVehSpdFA_Init_write_IRV: type=Boolean, init-value=0
          CanVehSpd_CANC2_Init_write_IRV: type=Float, init-value=0
          CanVehSpdFA_CANC2_Init_write_IRV: type=Boolean, init-value=0
          VehSpdVSOSigFailSts_Init_write_IRV: type=Boolean, init-value=0
          VehSpdVSOSigFailSts_CANC2_Init_write_IRV: type=Boolean, init-value=0
          VeCSVI_b_CanSigVehSpdSR_CANC2_Init_write_IRV: type=Boolean, init-value=0
          VeCSVI_b_VehSpdVSOSigFailStsSR_CANC2_Init_write_IRV: type=Boolean, init-value=0
          LeftFrontWhlFA_Init_write_IRV: type=Boolean, init-value=0
          LeftFrontWhl_Init_write_IRV: type=Float, init-value=0
          RightFrontWhlFA_Init_write_IRV: type=Boolean, init-value=0
          RightFrontWhl_Init_write_IRV: type=Float, init-value=0
          LeftFrontWhlDir_FA_Init_write_IRV: type=Boolean, init-value=0
          RightFrontWhlDir_FA_Init_write_IRV: type=Boolean, init-value=0
          OutSpdPolarityFA_initVal_write_IRV: type=Boolean, init-value=0
          OutSpdPolarity_initVal_write_IRV: type=TeCSVR_e_OutSpdDirection, init-value=CeCSVR_e_OutSpdDirectionUnknown
          LeftRearWhlFA_Init_write_IRV: type=Boolean, init-value=0
          LeftRearWhl_Init_write_IRV: type=Float, init-value=0
          RightRearWhlFA_Init_write_IRV: type=Boolean, init-value=0
          RightRearWhl_Init_write_IRV: type=Float, init-value=0
          LeftRearWhlDir_FA_Init_write_IRV: type=Boolean, init-value=0
          RightRearWhlDir_FA_Init_write_IRV: type=Boolean, init-value=0
          LeftRearWhlDir_Init_write_IRV: type=TeCSVR_e_Wheel_Direction, init-value=CeCSVR_e_WheelDirectionUnknown
          RightRearWhlDir_Init_write_IRV: type=TeCSVR_e_Wheel_Direction, init-value=CeCSVR_e_WheelDirectionUnknown
          TOSSnsrSpdRawFA_Init_write_IRV: type=Boolean, init-value=0
          TOS_SnsrSpdRaw_Init_write_IRV: type=Float, init-value=0
          RefVehSpd_Init_write_IRV: type=Float, init-value=0
          RefVehSpdFA_Init_write_IRV: type=Boolean, init-value=0
          LeftFrontWhlDir_Init_write_IRV: type=TeCSVR_e_Wheel_Direction, init-value=CeCSVR_e_WheelDirectionUnknown
          RightFrontWhlDir_Init_write_IRV: type=TeCSVR_e_Wheel_Direction, init-value=CeCSVR_e_WheelDirectionUnknown
          ST2InpSpd_Init_write_IRV: type=Float, init-value=0
          ST2InpSpdFA_Init_write_IRV: type=Boolean, init-value=0
          WheelSensorFailStsLHF_Init_write_IRV: type=Boolean, init-value=0
          WheelSensorFailStsLHR_Init_write_IRV: type=Boolean, init-value=0
          WheelSensorFailStsRHF_Init_write_IRV: type=Boolean, init-value=0
          WheelSensorFailStsRHR_Init_write_IRV: type=Boolean, init-value=0
          THA_STAT_Init_write_IRV: type=TeCSVR_e_THA_STAT, init-value=CeCSVR_e_THA_Initial
          THA_SpdLim_Init_write_IRV: type=TeCSVR_e_THA_SpdLim, init-value=CeCSVR_e_THAsl_NoRequest
          TRSC_STAT_Init_write_IRV: type=TeCSVR_e_TRSC_STAT, init-value=CeCSVR_e_TRSC_Standby
          TRSC_SpdLimReq_Init_write_IRV: type=TeCSVR_e_TRSC_SpdLimReq, init-value=CeCSVR_e_TRSCslr_NotLimiting
          THA_STATFA_Init_write_IRV: type=Boolean, init-value=0
          THA_SpdLimFA_Init_write_IRV: type=Boolean, init-value=0
          TRSC_STATFA_Init_write_IRV: type=Boolean, init-value=0
          TRSC_SpdLimReqFA_Init_write_IRV: type=Boolean, init-value=0
          VeCSVC_v_VehSpd_write_IRV: type=Float, init-value=0
      50 x runnable:
        CSVR_ac_Init
          data-send-points:
            17 x access:
              OUT_VeCSVR_e_FrontAxlSpdSrc_Value: accessed-variable=VeCSVR_e_FrontAxlSpdSrc.Value
              OUT_VeCSVR_e_RearAxlSpdSrc_Value: accessed-variable=VeCSVR_e_RearAxlSpdSrc.Value
              OUT_VeCSVR_e_VehSpdSrc_Value: accessed-variable=VeCSVR_e_VehSpdSrc.Value
              OUT_VeCSVR_e_TOS_VS_WhlError_Value: accessed-variable=VeCSVR_e_TOS_VS_WhlError.Value
              OUT_VeCSVR_e_NTurbSrcArb_Value: accessed-variable=VeCSVR_e_NTurbSrcArb.Value
              OUT_VeCSVR_e_TransOutSpdDir_Value: accessed-variable=VeCSVR_e_TransOutSpdDir.Value
              OUT_VeCSVR_e_FrontAxlDir_Value: accessed-variable=VeCSVR_e_FrontAxlDir.Value
              OUT_VeCSVR_e_RearAxlDir_Value: accessed-variable=VeCSVR_e_RearAxlDir.Value
              OUT_VeCSVR_e_FrontLeftWhlDir_Value: accessed-variable=VeCSVR_e_FrontLeftWhlDir.Value
              OUT_VeCSVR_e_RearLeftWhlDir_Value: accessed-variable=VeCSVR_e_RearLeftWhlDir.Value
              OUT_VeCSVR_e_FrontRightWhlDir_Value: accessed-variable=VeCSVR_e_FrontRightWhlDir.Value
              OUT_VeCSVR_e_RearRightWhlDir_Value: accessed-variable=VeCSVR_e_RearRightWhlDir.Value
              OUT_VeCSVR_e_FaultSts_VehSpd_OSS_Corr_Value: accessed-variable=VeCSVR_e_FaultSts_VehSpd_OSS_Corr.Value
              OUT_VeCSVR_e_THA_RespEVCU2_Value: accessed-variable=VeCSVR_e_THA_RespEVCU2.Value
              OUT_VeCSVR_e_TRSC_RespEVCU2_Value: accessed-variable=VeCSVR_e_TRSC_RespEVCU2.Value
              OUT_VeCSVR_e_THA_SpdLimInt_Value: accessed-variable=VeCSVR_e_THA_SpdLimInt.Value
              OUT_VeCSVR_e_TRSC_SpdLimReqInt_Value: accessed-variable=VeCSVR_e_TRSC_SpdLimReqInt.Value
        ClearCodes_CSVR
          data-receive-point-by-arguments:
            access IN_VeDIDR_b_PostCodeClrDiagDsbl_VeDIDR_b_PostCodeClrDiagDsbl: accessed-variable=VeDIDR_b_PostCodeClrDiagDsbl.VeDIDR_b_PostCodeClrDiagDsbl
          data-send-points:
            access OUT_VeCSVR_l_DistSinceCodeClr_Value: accessed-variable=VeCSVR_l_DistSinceCodeClr.Value
            access OUT_VeCSVR_l_DistTravelMIL_On_Value: accessed-variable=VeCSVR_l_DistTravelMIL_On.Value
        CSVR_PwrOn
          data-receive-point-by-arguments:
            6 x access:
              IN_NeCSVD_Cnt_FrontAxleRatlFlt_MFOP_Rx_NeCSVD_Cnt_FrontAxleRatlFlt_MFOP: accessed-variable=NeCSVD_Cnt_FrontAxleRatlFlt_MFOP_Rx.NeCSVD_Cnt_FrontAxleRatlFlt_MFOP
              IN_NeCSVD_Cnt_RearAxleRatlFlt_MFOP_Rx_NeCSVD_Cnt_RearAxleRatlFlt_MFOP: accessed-variable=NeCSVD_Cnt_RearAxleRatlFlt_MFOP_Rx.NeCSVD_Cnt_RearAxleRatlFlt_MFOP
              IN_NeCSVR_b_PriorMIL_StatusOn_Rx_NeCSVR_b_PriorMIL_StatusOn: accessed-variable=NeCSVR_b_PriorMIL_StatusOn_Rx.NeCSVR_b_PriorMIL_StatusOn
              IN_NeCSVR_e_MIL_LightRequest_Rx_NeCSVR_e_MIL_LightRequest: accessed-variable=NeCSVR_e_MIL_LightRequest_Rx.NeCSVR_e_MIL_LightRequest
              IN_NeCSVR_l_DistSinceCodeClr_Rx_NeCSVR_l_DistSinceCodeClr: accessed-variable=NeCSVR_l_DistSinceCodeClr_Rx.NeCSVR_l_DistSinceCodeClr
              IN_NeCSVR_l_DistTravelMIL_On_Rx_NeCSVR_l_DistTravelMIL_On: accessed-variable=NeCSVR_l_DistTravelMIL_On_Rx.NeCSVR_l_DistTravelMIL_On
          data-send-points:
            70 x access:
              OUT_VeCSVR_n_FrontAxlSpdSgndFltrd_Value: accessed-variable=VeCSVR_n_FrontAxlSpdSgndFltrd.Value
              OUT_VeCSVR_e_FrontAxlSpdSrc_Value: accessed-variable=VeCSVR_e_FrontAxlSpdSrc.Value
              OUT_VeCSVR_b_FrontAxlSpdFA_Value: accessed-variable=VeCSVR_b_FrontAxlSpdFA.Value
              OUT_VeCSVR_n_RearAxlSpdSgndFltrd_Value: accessed-variable=VeCSVR_n_RearAxlSpdSgndFltrd.Value
              OUT_VeCSVR_e_RearAxlSpdSrc_Value: accessed-variable=VeCSVR_e_RearAxlSpdSrc.Value
              OUT_VeCSVR_b_RearAxlSpdFA_Value: accessed-variable=VeCSVR_b_RearAxlSpdFA.Value
              OUT_VeCSVR_n_TransOutSpdSgndFltrd_Value: accessed-variable=VeCSVR_n_TransOutSpdSgndFltrd.Value
              OUT_VeCSVR_b_TransOutSpdFA_Value: accessed-variable=VeCSVR_b_TransOutSpdFA.Value
              OUT_VeCSVR_v_VehSpdSigned_Value: accessed-variable=VeCSVR_v_VehSpdSigned.Value
              OUT_VeCSVR_e_VehSpdSrc_Value: accessed-variable=VeCSVR_e_VehSpdSrc.Value
              OUT_VeCSVR_b_VehSpdFA_Value: accessed-variable=VeCSVR_b_VehSpdFA.Value
              OUT_VeCSVR_n_ReferenceNo_Value: accessed-variable=VeCSVR_n_ReferenceNo.Value
              OUT_VeCSVR_b_ReferenceNoFA_Value: accessed-variable=VeCSVR_b_ReferenceNoFA.Value
              OUT_VeCSVR_b_DsblFrontAxlSpdRatCheck_Value: accessed-variable=VeCSVR_b_DsblFrontAxlSpdRatCheck.Value
              OUT_VeCSVR_b_FrontAxleRatlFlt_FltDtct_Value: accessed-variable=VeCSVR_b_FrontAxleRatlFlt_FltDtct.Value
              OUT_VeCSVR_l_DistSinceCodeClr_Value: accessed-variable=VeCSVR_l_DistSinceCodeClr.Value
              OUT_VeCSVR_l_DistTravelMIL_On_Value: accessed-variable=VeCSVR_l_DistTravelMIL_On.Value
              OUT_VeCSVR_b_PrimWhlSpdSignedFA_Value: accessed-variable=VeCSVR_b_PrimWhlSpdSignedFA.Value
              OUT_VeCSVR_n_PrimWhlSpdSigned_Value: accessed-variable=VeCSVR_n_PrimWhlSpdSigned.Value
              OUT_VeCSVR_dn_FrontAxlSpddot_Value: accessed-variable=VeCSVR_dn_FrontAxlSpddot.Value
              OUT_VeCSVR_dn_TransOutSpddot_Value: accessed-variable=VeCSVR_dn_TransOutSpddot.Value
              OUT_VeCSVR_dn_RearAxlSpddot_Value: accessed-variable=VeCSVR_dn_RearAxlSpddot.Value
              OUT_VeCSVR_a_VehAccel_Value: accessed-variable=VeCSVR_a_VehAccel.Value
              OUT_VeCSVR_n_NTurbArb_Value: accessed-variable=VeCSVR_n_NTurbArb.Value
              OUT_VeCSVR_b_NTurbFA_Value: accessed-variable=VeCSVR_b_NTurbFA.Value
              OUT_VeCSVR_n_FrontAxlSpdSgndRaw_Value: accessed-variable=VeCSVR_n_FrontAxlSpdSgndRaw.Value
              OUT_VeCSVR_n_RearAxlSpdSgndRaw_Value: accessed-variable=VeCSVR_n_RearAxlSpdSgndRaw.Value
              OUT_VeCSVR_n_TransOutSpdSgndRaw_Value: accessed-variable=VeCSVR_n_TransOutSpdSgndRaw.Value
              OUT_VeCSVR_v_VehSpd_Value: accessed-variable=VeCSVR_v_VehSpd.Value
              OUT_VeCSVR_v_LeftFrontWheel_Value: accessed-variable=VeCSVR_v_LeftFrontWheel.Value
              OUT_VeCSVR_v_RightFrontWheel_Value: accessed-variable=VeCSVR_v_RightFrontWheel.Value
              OUT_VeCSVR_e_TOS_VS_WhlError_Value: accessed-variable=VeCSVR_e_TOS_VS_WhlError.Value
              OUT_VeCSVR_b_TOS_DirectionError_Value: accessed-variable=VeCSVR_b_TOS_DirectionError.Value
              OUT_VeCSVR_v_CanSigVehSpd_Value: accessed-variable=VeCSVR_v_CanSigVehSpd.Value
              OUT_VeCSVR_l_WhlRadius_Value: accessed-variable=VeCSVR_l_WhlRadius.Value
              OUT_VeCSVR_e_NTurbSrcArb_Value: accessed-variable=VeCSVR_e_NTurbSrcArb.Value
              OUT_VeCSVR_b_NTurbArbFA_Value: accessed-variable=VeCSVR_b_NTurbArbFA.Value
              OUT_VeCSVR_n_ST2InpSpd_Value: accessed-variable=VeCSVR_n_ST2InpSpd.Value
              OUT_VeCSVR_b_ST2InpSpdFA_Value: accessed-variable=VeCSVR_b_ST2InpSpdFA.Value
              OUT_VeCSVR_b_VehSpdVSOSigFailSts_Value: accessed-variable=VeCSVR_b_VehSpdVSOSigFailSts.Value
              OUT_VeCSVR_b_CanSigVehSpd_FA_Value: accessed-variable=VeCSVR_b_CanSigVehSpd_FA.Value
              OUT_VeCSVR_e_TransOutSpdDir_Value: accessed-variable=VeCSVR_e_TransOutSpdDir.Value
              OUT_VeCSVR_v_VehSpdRaw_Value: accessed-variable=VeCSVR_v_VehSpdRaw.Value
              OUT_VeCSVR_n_WhlSpdLHF_Value: accessed-variable=VeCSVR_n_WhlSpdLHF.Value
              OUT_VeCSVR_n_WhlSpdLHR_Value: accessed-variable=VeCSVR_n_WhlSpdLHR.Value
              OUT_VeCSVR_n_WhlSpdRHF_Value: accessed-variable=VeCSVR_n_WhlSpdRHF.Value
              OUT_VeCSVR_n_WhlSpdRHR_Value: accessed-variable=VeCSVR_n_WhlSpdRHR.Value
              OUT_VeCSVR_b_WhlSpdLHF_FA_Value: accessed-variable=VeCSVR_b_WhlSpdLHF_FA.Value
              OUT_VeCSVR_b_WhlSpdLHR_FA_Value: accessed-variable=VeCSVR_b_WhlSpdLHR_FA.Value
              OUT_VeCSVR_b_WhlSpdRHF_FA_Value: accessed-variable=VeCSVR_b_WhlSpdRHF_FA.Value
              OUT_VeCSVR_b_WhlSpdRHR_FA_Value: accessed-variable=VeCSVR_b_WhlSpdRHR_FA.Value
              OUT_VeCSVR_b_WheelSensorFailStsLHF_Value: accessed-variable=VeCSVR_b_WheelSensorFailStsLHF.Value
              OUT_VeCSVR_b_WheelSensorFailStsLHR_Value: accessed-variable=VeCSVR_b_WheelSensorFailStsLHR.Value
              OUT_VeCSVR_b_WheelSensorFailStsRHF_Value: accessed-variable=VeCSVR_b_WheelSensorFailStsRHF.Value
              OUT_VeCSVR_b_WheelSensorFailStsRHR_Value: accessed-variable=VeCSVR_b_WheelSensorFailStsRHR.Value
              OUT_VeCSVR_e_FrontAxlDir_Value: accessed-variable=VeCSVR_e_FrontAxlDir.Value
              OUT_VeCSVR_e_RearAxlDir_Value: accessed-variable=VeCSVR_e_RearAxlDir.Value
              OUT_VeCSVR_v_LeftRearWheel_Value: accessed-variable=VeCSVR_v_LeftRearWheel.Value
              OUT_VeCSVR_v_RightRearWheel_Value: accessed-variable=VeCSVR_v_RightRearWheel.Value
              OUT_VeCSVR_e_FrontLeftWhlDir_Value: accessed-variable=VeCSVR_e_FrontLeftWhlDir.Value
              OUT_VeCSVR_e_RearLeftWhlDir_Value: accessed-variable=VeCSVR_e_RearLeftWhlDir.Value
              OUT_VeCSVR_e_FrontRightWhlDir_Value: accessed-variable=VeCSVR_e_FrontRightWhlDir.Value
              OUT_VeCSVR_e_RearRightWhlDir_Value: accessed-variable=VeCSVR_e_RearRightWhlDir.Value
              OUT_VeCSVR_b_SecWhlSpdSignedFA_Value: accessed-variable=VeCSVR_b_SecWhlSpdSignedFA.Value
              OUT_VeCSVR_n_SecWhlSpdSigned_Value: accessed-variable=VeCSVR_n_SecWhlSpdSigned.Value
              OUT_VeCSVR_e_FaultSts_VehSpd_OSS_Corr_Value: accessed-variable=VeCSVR_e_FaultSts_VehSpd_OSS_Corr.Value
              OUT_VeCSVR_e_THA_RespEVCU2_Value: accessed-variable=VeCSVR_e_THA_RespEVCU2.Value
              OUT_VeCSVR_e_TRSC_RespEVCU2_Value: accessed-variable=VeCSVR_e_TRSC_RespEVCU2.Value
              OUT_VeCSVR_e_THA_SpdLimInt_Value: accessed-variable=VeCSVR_e_THA_SpdLimInt.Value
              OUT_VeCSVR_e_TRSC_SpdLimReqInt_Value: accessed-variable=VeCSVR_e_TRSC_SpdLimReqInt.Value
          written-local-variables:
            47 x access:
              WV_CanVehSpdFA_CANC2_Init_write_IRV: accessed-variable=CanVehSpdFA_CANC2_Init_write_IRV
              WV_CanVehSpdFA_Init_write_IRV: accessed-variable=CanVehSpdFA_Init_write_IRV
              WV_CanVehSpd_CANC2_Init_write_IRV: accessed-variable=CanVehSpd_CANC2_Init_write_IRV
              WV_CanVehSpd_Init_write_IRV: accessed-variable=CanVehSpd_Init_write_IRV
              WV_LeftFrontWhlDir_FA_Init_write_IRV: accessed-variable=LeftFrontWhlDir_FA_Init_write_IRV
              WV_LeftFrontWhlDir_Init_write_IRV: accessed-variable=LeftFrontWhlDir_Init_write_IRV
              WV_LeftFrontWhlFA_Init_write_IRV: accessed-variable=LeftFrontWhlFA_Init_write_IRV
              WV_LeftFrontWhl_Init_write_IRV: accessed-variable=LeftFrontWhl_Init_write_IRV
              WV_LeftRearWhlDir_FA_Init_write_IRV: accessed-variable=LeftRearWhlDir_FA_Init_write_IRV
              WV_LeftRearWhlDir_Init_write_IRV: accessed-variable=LeftRearWhlDir_Init_write_IRV
              WV_LeftRearWhlFA_Init_write_IRV: accessed-variable=LeftRearWhlFA_Init_write_IRV
              WV_LeftRearWhl_Init_write_IRV: accessed-variable=LeftRearWhl_Init_write_IRV
              WV_NturbFA_Init_write_IRV: accessed-variable=NturbFA_Init_write_IRV
              WV_Nturb_Init_write_IRV: accessed-variable=Nturb_Init_write_IRV
              WV_OutSpdPolarityFA_initVal_write_IRV: accessed-variable=OutSpdPolarityFA_initVal_write_IRV
              WV_OutSpdPolarity_initVal_write_IRV: accessed-variable=OutSpdPolarity_initVal_write_IRV
              WV_RefVehSpdFA_Init_write_IRV: accessed-variable=RefVehSpdFA_Init_write_IRV
              WV_RefVehSpd_Init_write_IRV: accessed-variable=RefVehSpd_Init_write_IRV
              WV_RightFrontWhlDir_FA_Init_write_IRV: accessed-variable=RightFrontWhlDir_FA_Init_write_IRV
              WV_RightFrontWhlDir_Init_write_IRV: accessed-variable=RightFrontWhlDir_Init_write_IRV
              WV_RightFrontWhlFA_Init_write_IRV: accessed-variable=RightFrontWhlFA_Init_write_IRV
              WV_RightFrontWhl_Init_write_IRV: accessed-variable=RightFrontWhl_Init_write_IRV
              WV_RightRearWhlDir_FA_Init_write_IRV: accessed-variable=RightRearWhlDir_FA_Init_write_IRV
              WV_RightRearWhlDir_Init_write_IRV: accessed-variable=RightRearWhlDir_Init_write_IRV
              WV_RightRearWhlFA_Init_write_IRV: accessed-variable=RightRearWhlFA_Init_write_IRV
              WV_RightRearWhl_Init_write_IRV: accessed-variable=RightRearWhl_Init_write_IRV
              WV_ST2InpSpdFA_Init_write_IRV: accessed-variable=ST2InpSpdFA_Init_write_IRV
              WV_ST2InpSpd_Init_write_IRV: accessed-variable=ST2InpSpd_Init_write_IRV
              WV_THA_STATFA_Init_write_IRV: accessed-variable=THA_STATFA_Init_write_IRV
              WV_THA_STAT_Init_write_IRV: accessed-variable=THA_STAT_Init_write_IRV
              WV_THA_SpdLimFA_Init_write_IRV: accessed-variable=THA_SpdLimFA_Init_write_IRV
              WV_THA_SpdLim_Init_write_IRV: accessed-variable=THA_SpdLim_Init_write_IRV
              WV_TOSSnsrSpdRawFA_Init_write_IRV: accessed-variable=TOSSnsrSpdRawFA_Init_write_IRV
              WV_TOS_SnsrSpdRaw_Init_write_IRV: accessed-variable=TOS_SnsrSpdRaw_Init_write_IRV
              WV_TRSC_STATFA_Init_write_IRV: accessed-variable=TRSC_STATFA_Init_write_IRV
              WV_TRSC_STAT_Init_write_IRV: accessed-variable=TRSC_STAT_Init_write_IRV
              WV_TRSC_SpdLimReqFA_Init_write_IRV: accessed-variable=TRSC_SpdLimReqFA_Init_write_IRV
              WV_TRSC_SpdLimReq_Init_write_IRV: accessed-variable=TRSC_SpdLimReq_Init_write_IRV
              WV_VeCSVC_v_VehSpd_write_IRV: accessed-variable=VeCSVC_v_VehSpd_write_IRV
              WV_VeCSVI_b_CanSigVehSpdSR_CANC2_Init_write_IRV: accessed-variable=VeCSVI_b_CanSigVehSpdSR_CANC2_Init_write_IRV
              WV_VeCSVI_b_VehSpdVSOSigFailStsSR_CANC2_Init_write_IRV: accessed-variable=VeCSVI_b_VehSpdVSOSigFailStsSR_CANC2_Init_write_IRV
              WV_VehSpdVSOSigFailSts_CANC2_Init_write_IRV: accessed-variable=VehSpdVSOSigFailSts_CANC2_Init_write_IRV
              WV_VehSpdVSOSigFailSts_Init_write_IRV: accessed-variable=VehSpdVSOSigFailSts_Init_write_IRV
              WV_WheelSensorFailStsLHF_Init_write_IRV: accessed-variable=WheelSensorFailStsLHF_Init_write_IRV
              WV_WheelSensorFailStsLHR_Init_write_IRV: accessed-variable=WheelSensorFailStsLHR_Init_write_IRV
              WV_WheelSensorFailStsRHF_Init_write_IRV: accessed-variable=WheelSensorFailStsRHF_Init_write_IRV
              WV_WheelSensorFailStsRHR_Init_write_IRV: accessed-variable=WheelSensorFailStsRHR_Init_write_IRV
        CSVR_FastTEF
          data-receive-point-by-arguments:
            27 x access:
              IN_VaOSMR_n_NTurb_FromNo_Value: accessed-variable=VaOSMR_n_NTurb_FromNo.Value
              IN_VeADCR_e_WEDAxleStat_Value: accessed-variable=VeADCR_e_WEDAxleStat.Value
              IN_VeBSWR_e_MIL_Request_Value: accessed-variable=VeBSWR_e_MIL_Request.Value
              IN_VeDFIR_b_DsblDiagFailSafe_Value: accessed-variable=VeDFIR_b_DsblDiagFailSafe.Value
              IN_VeDFIR_b_PostCodeClrDiagDsbl_Value: accessed-variable=VeDFIR_b_PostCodeClrDiagDsbl.Value
              IN_VeDMAB_y_StatusByte_VehSpd_OSS_Corr_Value: accessed-variable=VeDMAB_y_StatusByte_VehSpd_OSS_Corr.Value
              IN_VeFWDR_e_Tcase_Stat_Value: accessed-variable=VeFWDR_e_Tcase_Stat.Value
              IN_VeFWDR_r_Axle_Ratio_Value: accessed-variable=VeFWDR_r_Axle_Ratio.Value
              IN_VeFWDR_r_TCaseRatio_Value: accessed-variable=VeFWDR_r_TCaseRatio.Value
              IN_VeMSPR_b_MtrA_SpdFA_Value: accessed-variable=VeMSPR_b_MtrA_SpdFA.Value
              IN_VeMSPR_b_MtrB_SpdFA_Value: accessed-variable=VeMSPR_b_MtrB_SpdFA.Value
              IN_VeMSPR_b_MtrC_SpdFA_Value: accessed-variable=VeMSPR_b_MtrC_SpdFA.Value
              IN_VeMSPR_e_MtrASpd_Src_Value: accessed-variable=VeMSPR_e_MtrASpd_Src.Value
              IN_VeMSPR_e_MtrBSpd_Src_Value: accessed-variable=VeMSPR_e_MtrBSpd_Src.Value
              IN_VeMSPR_e_MtrCSpd_Src_Value: accessed-variable=VeMSPR_e_MtrCSpd_Src.Value
              IN_VeMSPR_n_MtrA_Spd_Value: accessed-variable=VeMSPR_n_MtrA_Spd.Value
              IN_VeMSPR_n_MtrB_Spd_Value: accessed-variable=VeMSPR_n_MtrB_Spd.Value
              IN_VeMSPR_n_MtrC_Spd_Value: accessed-variable=VeMSPR_n_MtrC_Spd.Value
              IN_VeOSMR_e_ActualGear_Value: accessed-variable=VeOSMR_e_ActualGear.Value
              IN_VeOSMR_e_TargetGear_Value: accessed-variable=VeOSMR_e_TargetGear.Value
              IN_VePRXR_l_WhlRadius_Value: accessed-variable=VePRXR_l_WhlRadius.Value
              IN_VeTISR_n_InputSpeed_Value: accessed-variable=VeTISR_n_InputSpeed.Value
              IN_VeTRGR_e_CurrentGear_Value: accessed-variable=VeTRGR_e_CurrentGear.Value
              IN_VeTRNR_b_ActualGearFA_Value: accessed-variable=VeTRNR_b_ActualGearFA.Value
              IN_VeTRNR_b_TargetGearFA_Value: accessed-variable=VeTRNR_b_TargetGearFA.Value
              IN_VeTRNR_e_ActualGear_Value: accessed-variable=VeTRNR_e_ActualGear.Value
              IN_VeTRNR_e_TargetGear_Value: accessed-variable=VeTRNR_e_TargetGear.Value
          data-send-points:
            68 x access:
              OUT_VeCSVR_n_FrontAxlSpdSgndFltrd_Value: accessed-variable=VeCSVR_n_FrontAxlSpdSgndFltrd.Value
              OUT_VeCSVR_e_FrontAxlSpdSrc_Value: accessed-variable=VeCSVR_e_FrontAxlSpdSrc.Value
              OUT_VeCSVR_b_FrontAxlSpdFA_Value: accessed-variable=VeCSVR_b_FrontAxlSpdFA.Value
              OUT_VeCSVR_n_RearAxlSpdSgndFltrd_Value: accessed-variable=VeCSVR_n_RearAxlSpdSgndFltrd.Value
              OUT_VeCSVR_e_RearAxlSpdSrc_Value: accessed-variable=VeCSVR_e_RearAxlSpdSrc.Value
              OUT_VeCSVR_b_RearAxlSpdFA_Value: accessed-variable=VeCSVR_b_RearAxlSpdFA.Value
              OUT_VeCSVR_n_TransOutSpdSgndFltrd_Value: accessed-variable=VeCSVR_n_TransOutSpdSgndFltrd.Value
              OUT_VeCSVR_b_TransOutSpdFA_Value: accessed-variable=VeCSVR_b_TransOutSpdFA.Value
              OUT_VeCSVR_v_VehSpdSigned_Value: accessed-variable=VeCSVR_v_VehSpdSigned.Value
              OUT_VeCSVR_e_VehSpdSrc_Value: accessed-variable=VeCSVR_e_VehSpdSrc.Value
              OUT_VeCSVR_b_VehSpdFA_Value: accessed-variable=VeCSVR_b_VehSpdFA.Value
              OUT_VeCSVR_n_ReferenceNo_Value: accessed-variable=VeCSVR_n_ReferenceNo.Value
              OUT_VeCSVR_b_ReferenceNoFA_Value: accessed-variable=VeCSVR_b_ReferenceNoFA.Value
              OUT_VeCSVR_b_DsblFrontAxlSpdRatCheck_Value: accessed-variable=VeCSVR_b_DsblFrontAxlSpdRatCheck.Value
              OUT_VeCSVR_b_FrontAxleRatlFlt_FltDtct_Value: accessed-variable=VeCSVR_b_FrontAxleRatlFlt_FltDtct.Value
              OUT_VeCSVR_b_PrimWhlSpdSignedFA_Value: accessed-variable=VeCSVR_b_PrimWhlSpdSignedFA.Value
              OUT_VeCSVR_n_PrimWhlSpdSigned_Value: accessed-variable=VeCSVR_n_PrimWhlSpdSigned.Value
              OUT_VeCSVR_dn_FrontAxlSpddot_Value: accessed-variable=VeCSVR_dn_FrontAxlSpddot.Value
              OUT_VeCSVR_dn_TransOutSpddot_Value: accessed-variable=VeCSVR_dn_TransOutSpddot.Value
              OUT_VeCSVR_dn_RearAxlSpddot_Value: accessed-variable=VeCSVR_dn_RearAxlSpddot.Value
              OUT_VeCSVR_a_VehAccel_Value: accessed-variable=VeCSVR_a_VehAccel.Value
              OUT_VeCSVR_n_NTurbArb_Value: accessed-variable=VeCSVR_n_NTurbArb.Value
              OUT_VeCSVR_b_NTurbFA_Value: accessed-variable=VeCSVR_b_NTurbFA.Value
              OUT_VeCSVR_n_FrontAxlSpdSgndRaw_Value: accessed-variable=VeCSVR_n_FrontAxlSpdSgndRaw.Value
              OUT_VeCSVR_n_RearAxlSpdSgndRaw_Value: accessed-variable=VeCSVR_n_RearAxlSpdSgndRaw.Value
              OUT_VeCSVR_n_TransOutSpdSgndRaw_Value: accessed-variable=VeCSVR_n_TransOutSpdSgndRaw.Value
              OUT_VeCSVR_v_VehSpd_Value: accessed-variable=VeCSVR_v_VehSpd.Value
              OUT_VeCSVR_v_LeftFrontWheel_Value: accessed-variable=VeCSVR_v_LeftFrontWheel.Value
              OUT_VeCSVR_v_RightFrontWheel_Value: accessed-variable=VeCSVR_v_RightFrontWheel.Value
              OUT_VeCSVR_e_TOS_VS_WhlError_Value: accessed-variable=VeCSVR_e_TOS_VS_WhlError.Value
              OUT_VeCSVR_b_TOS_DirectionError_Value: accessed-variable=VeCSVR_b_TOS_DirectionError.Value
              OUT_VeCSVR_v_CanSigVehSpd_Value: accessed-variable=VeCSVR_v_CanSigVehSpd.Value
              OUT_VeCSVR_l_WhlRadius_Value: accessed-variable=VeCSVR_l_WhlRadius.Value
              OUT_VeCSVR_e_NTurbSrcArb_Value: accessed-variable=VeCSVR_e_NTurbSrcArb.Value
              OUT_VeCSVR_b_NTurbArbFA_Value: accessed-variable=VeCSVR_b_NTurbArbFA.Value
              OUT_VeCSVR_n_ST2InpSpd_Value: accessed-variable=VeCSVR_n_ST2InpSpd.Value
              OUT_VeCSVR_b_ST2InpSpdFA_Value: accessed-variable=VeCSVR_b_ST2InpSpdFA.Value
              OUT_VeCSVR_b_VehSpdVSOSigFailSts_Value: accessed-variable=VeCSVR_b_VehSpdVSOSigFailSts.Value
              OUT_VeCSVR_b_CanSigVehSpd_FA_Value: accessed-variable=VeCSVR_b_CanSigVehSpd_FA.Value
              OUT_VeCSVR_e_TransOutSpdDir_Value: accessed-variable=VeCSVR_e_TransOutSpdDir.Value
              OUT_VeCSVR_v_VehSpdRaw_Value: accessed-variable=VeCSVR_v_VehSpdRaw.Value
              OUT_VeCSVR_n_WhlSpdLHF_Value: accessed-variable=VeCSVR_n_WhlSpdLHF.Value
              OUT_VeCSVR_n_WhlSpdLHR_Value: accessed-variable=VeCSVR_n_WhlSpdLHR.Value
              OUT_VeCSVR_n_WhlSpdRHF_Value: accessed-variable=VeCSVR_n_WhlSpdRHF.Value
              OUT_VeCSVR_n_WhlSpdRHR_Value: accessed-variable=VeCSVR_n_WhlSpdRHR.Value
              OUT_VeCSVR_b_WhlSpdLHF_FA_Value: accessed-variable=VeCSVR_b_WhlSpdLHF_FA.Value
              OUT_VeCSVR_b_WhlSpdLHR_FA_Value: accessed-variable=VeCSVR_b_WhlSpdLHR_FA.Value
              OUT_VeCSVR_b_WhlSpdRHF_FA_Value: accessed-variable=VeCSVR_b_WhlSpdRHF_FA.Value
              OUT_VeCSVR_b_WhlSpdRHR_FA_Value: accessed-variable=VeCSVR_b_WhlSpdRHR_FA.Value
              OUT_VeCSVR_b_WheelSensorFailStsLHF_Value: accessed-variable=VeCSVR_b_WheelSensorFailStsLHF.Value
              OUT_VeCSVR_b_WheelSensorFailStsLHR_Value: accessed-variable=VeCSVR_b_WheelSensorFailStsLHR.Value
              OUT_VeCSVR_b_WheelSensorFailStsRHF_Value: accessed-variable=VeCSVR_b_WheelSensorFailStsRHF.Value
              OUT_VeCSVR_b_WheelSensorFailStsRHR_Value: accessed-variable=VeCSVR_b_WheelSensorFailStsRHR.Value
              OUT_VeCSVR_e_FrontAxlDir_Value: accessed-variable=VeCSVR_e_FrontAxlDir.Value
              OUT_VeCSVR_e_RearAxlDir_Value: accessed-variable=VeCSVR_e_RearAxlDir.Value
              OUT_VeCSVR_v_LeftRearWheel_Value: accessed-variable=VeCSVR_v_LeftRearWheel.Value
              OUT_VeCSVR_v_RightRearWheel_Value: accessed-variable=VeCSVR_v_RightRearWheel.Value
              OUT_VeCSVR_e_FrontLeftWhlDir_Value: accessed-variable=VeCSVR_e_FrontLeftWhlDir.Value
              OUT_VeCSVR_e_RearLeftWhlDir_Value: accessed-variable=VeCSVR_e_RearLeftWhlDir.Value
              OUT_VeCSVR_e_FrontRightWhlDir_Value: accessed-variable=VeCSVR_e_FrontRightWhlDir.Value
              OUT_VeCSVR_e_RearRightWhlDir_Value: accessed-variable=VeCSVR_e_RearRightWhlDir.Value
              OUT_VeCSVR_b_SecWhlSpdSignedFA_Value: accessed-variable=VeCSVR_b_SecWhlSpdSignedFA.Value
              OUT_VeCSVR_n_SecWhlSpdSigned_Value: accessed-variable=VeCSVR_n_SecWhlSpdSigned.Value
              OUT_VeCSVR_e_FaultSts_VehSpd_OSS_Corr_Value: accessed-variable=VeCSVR_e_FaultSts_VehSpd_OSS_Corr.Value
              OUT_VeCSVR_e_TRSC_SpdLimReqInt_Value: accessed-variable=VeCSVR_e_TRSC_SpdLimReqInt.Value
              OUT_VeCSVR_e_THA_SpdLimInt_Value: accessed-variable=VeCSVR_e_THA_SpdLimInt.Value
              OUT_VeCSVR_e_THA_RespEVCU2_Value: accessed-variable=VeCSVR_e_THA_RespEVCU2.Value
              OUT_VeCSVR_e_TRSC_RespEVCU2_Value: accessed-variable=VeCSVR_e_TRSC_RespEVCU2.Value
          read-local-variables:
            46 x access:
              RV_CanVehSpdFA_CANC2_Init_write_IRV: accessed-variable=CanVehSpdFA_CANC2_Init_write_IRV
              RV_CanVehSpdFA_Init_write_IRV: accessed-variable=CanVehSpdFA_Init_write_IRV
              RV_CanVehSpd_CANC2_Init_write_IRV: accessed-variable=CanVehSpd_CANC2_Init_write_IRV
              RV_CanVehSpd_Init_write_IRV: accessed-variable=CanVehSpd_Init_write_IRV
              RV_LeftFrontWhlDir_FA_Init_write_IRV: accessed-variable=LeftFrontWhlDir_FA_Init_write_IRV
              RV_LeftFrontWhlDir_Init_write_IRV: accessed-variable=LeftFrontWhlDir_Init_write_IRV
              RV_LeftFrontWhlFA_Init_write_IRV: accessed-variable=LeftFrontWhlFA_Init_write_IRV
              RV_LeftFrontWhl_Init_write_IRV: accessed-variable=LeftFrontWhl_Init_write_IRV
              RV_LeftRearWhlDir_FA_Init_write_IRV: accessed-variable=LeftRearWhlDir_FA_Init_write_IRV
              RV_LeftRearWhlDir_Init_write_IRV: accessed-variable=LeftRearWhlDir_Init_write_IRV
              RV_LeftRearWhlFA_Init_write_IRV: accessed-variable=LeftRearWhlFA_Init_write_IRV
              RV_LeftRearWhl_Init_write_IRV: accessed-variable=LeftRearWhl_Init_write_IRV
              RV_NturbFA_Init_write_IRV: accessed-variable=NturbFA_Init_write_IRV
              RV_Nturb_Init_write_IRV: accessed-variable=Nturb_Init_write_IRV
              RV_OutSpdPolarityFA_initVal_write_IRV: accessed-variable=OutSpdPolarityFA_initVal_write_IRV
              RV_OutSpdPolarity_initVal_write_IRV: accessed-variable=OutSpdPolarity_initVal_write_IRV
              RV_RefVehSpdFA_Init_write_IRV: accessed-variable=RefVehSpdFA_Init_write_IRV
              RV_RefVehSpd_Init_write_IRV: accessed-variable=RefVehSpd_Init_write_IRV
              RV_RightFrontWhlDir_FA_Init_write_IRV: accessed-variable=RightFrontWhlDir_FA_Init_write_IRV
              RV_RightFrontWhlDir_Init_write_IRV: accessed-variable=RightFrontWhlDir_Init_write_IRV
              RV_RightFrontWhlFA_Init_write_IRV: accessed-variable=RightFrontWhlFA_Init_write_IRV
              RV_RightFrontWhl_Init_write_IRV: accessed-variable=RightFrontWhl_Init_write_IRV
              RV_RightRearWhlDir_FA_Init_write_IRV: accessed-variable=RightRearWhlDir_FA_Init_write_IRV
              RV_RightRearWhlDir_Init_write_IRV: accessed-variable=RightRearWhlDir_Init_write_IRV
              RV_RightRearWhlFA_Init_write_IRV: accessed-variable=RightRearWhlFA_Init_write_IRV
              RV_RightRearWhl_Init_write_IRV: accessed-variable=RightRearWhl_Init_write_IRV
              RV_ST2InpSpdFA_Init_write_IRV: accessed-variable=ST2InpSpdFA_Init_write_IRV
              RV_ST2InpSpd_Init_write_IRV: accessed-variable=ST2InpSpd_Init_write_IRV
              RV_THA_STATFA_Init_write_IRV: accessed-variable=THA_STATFA_Init_write_IRV
              RV_THA_STAT_Init_write_IRV: accessed-variable=THA_STAT_Init_write_IRV
              RV_THA_SpdLimFA_Init_write_IRV: accessed-variable=THA_SpdLimFA_Init_write_IRV
              RV_THA_SpdLim_Init_write_IRV: accessed-variable=THA_SpdLim_Init_write_IRV
              RV_TOSSnsrSpdRawFA_Init_write_IRV: accessed-variable=TOSSnsrSpdRawFA_Init_write_IRV
              RV_TOS_SnsrSpdRaw_Init_write_IRV: accessed-variable=TOS_SnsrSpdRaw_Init_write_IRV
              RV_TRSC_STATFA_Init_write_IRV: accessed-variable=TRSC_STATFA_Init_write_IRV
              RV_TRSC_STAT_Init_write_IRV: accessed-variable=TRSC_STAT_Init_write_IRV
              RV_TRSC_SpdLimReqFA_Init_write_IRV: accessed-variable=TRSC_SpdLimReqFA_Init_write_IRV
              RV_TRSC_SpdLimReq_Init_write_IRV: accessed-variable=TRSC_SpdLimReq_Init_write_IRV
              RV_VeCSVI_b_CanSigVehSpdSR_CANC2_Init_write_IRV: accessed-variable=VeCSVI_b_CanSigVehSpdSR_CANC2_Init_write_IRV
              RV_VeCSVI_b_VehSpdVSOSigFailStsSR_CANC2_Init_write_IRV: accessed-variable=VeCSVI_b_VehSpdVSOSigFailStsSR_CANC2_Init_write_IRV
              RV_VehSpdVSOSigFailSts_CANC2_Init_write_IRV: accessed-variable=VehSpdVSOSigFailSts_CANC2_Init_write_IRV
              RV_VehSpdVSOSigFailSts_Init_write_IRV: accessed-variable=VehSpdVSOSigFailSts_Init_write_IRV
              RV_WheelSensorFailStsLHF_Init_write_IRV: accessed-variable=WheelSensorFailStsLHF_Init_write_IRV
              RV_WheelSensorFailStsLHR_Init_write_IRV: accessed-variable=WheelSensorFailStsLHR_Init_write_IRV
              RV_WheelSensorFailStsRHF_Init_write_IRV: accessed-variable=WheelSensorFailStsRHF_Init_write_IRV
              RV_WheelSensorFailStsRHR_Init_write_IRV: accessed-variable=WheelSensorFailStsRHR_Init_write_IRV
          written-local-variables:
            access WV_VeCSVC_v_VehSpd_write_IRV: accessed-variable=VeCSVC_v_VehSpd_write_IRV
        CSVR_SlowTEF
          data-receive-point-by-arguments:
            access IN_VeDFIR_cnt_NumEmissionDTC_Value: accessed-variable=VeDFIR_cnt_NumEmissionDTC.Value
            access IN_VePMDR_b_RunCrankActive_Value: accessed-variable=VePMDR_b_RunCrankActive.Value
          data-send-points:
            access OUT_VeCSVR_l_DistSinceCodeClr_Value: accessed-variable=VeCSVR_l_DistSinceCodeClr.Value
            access OUT_VeCSVR_l_DistTravelMIL_On_Value: accessed-variable=VeCSVR_l_DistTravelMIL_On.Value
          read-local-variables:
            access RV_VeCSVC_v_VehSpd_write_IRV: accessed-variable=VeCSVC_v_VehSpd_write_IRV
        CSVR_PwrOff
          data-send-points:
            6 x access:
              OUT_NeCSVR_e_MIL_LightRequest_NeCSVR_e_MIL_LightRequest: accessed-variable=NeCSVR_e_MIL_LightRequest.NeCSVR_e_MIL_LightRequest
              OUT_NeCSVR_l_DistSinceCodeClr_NeCSVR_l_DistSinceCodeClr: accessed-variable=NeCSVR_l_DistSinceCodeClr.NeCSVR_l_DistSinceCodeClr
              OUT_NeCSVR_b_PriorMIL_StatusOn_NeCSVR_b_PriorMIL_StatusOn: accessed-variable=NeCSVR_b_PriorMIL_StatusOn.NeCSVR_b_PriorMIL_StatusOn
              OUT_NeCSVR_l_DistTravelMIL_On_NeCSVR_l_DistTravelMIL_On: accessed-variable=NeCSVR_l_DistTravelMIL_On.NeCSVR_l_DistTravelMIL_On
              OUT_NeCSVD_Cnt_FrontAxleRatlFlt_MFOP_NeCSVD_Cnt_FrontAxleRatlFlt_MFOP: accessed-variable=NeCSVD_Cnt_FrontAxleRatlFlt_MFOP.NeCSVD_Cnt_FrontAxleRatlFlt_MFOP
              OUT_NeCSVD_Cnt_RearAxleRatlFlt_MFOP_NeCSVD_Cnt_RearAxleRatlFlt_MFOP: accessed-variable=NeCSVD_Cnt_RearAxleRatlFlt_MFOP.NeCSVD_Cnt_RearAxleRatlFlt_MFOP
        FsftCSVR_b_THA_STAT
          written-local-variables:
            access WV_THA_STATFA_Init_write_IRV: accessed-variable=THA_STATFA_Init_write_IRV
        FsftCSVR_b_THA_SpdLim
          written-local-variables:
            access WV_THA_SpdLimFA_Init_write_IRV: accessed-variable=THA_SpdLimFA_Init_write_IRV
        FsftCSVR_b_TRSC_STAT
          written-local-variables:
            access WV_TRSC_STATFA_Init_write_IRV: accessed-variable=TRSC_STATFA_Init_write_IRV
        FsftCSVR_b_TRSC_SpdLimReq
          written-local-variables:
            access WV_TRSC_SpdLimReqFA_Init_write_IRV: accessed-variable=TRSC_SpdLimReqFA_Init_write_IRV
        FsftCSVR_e_LeftFrontWhlDir
          written-local-variables:
            access WV_LeftFrontWhlDir_FA_Init_write_IRV: accessed-variable=LeftFrontWhlDir_FA_Init_write_IRV
            access WV_LeftFrontWhlDir_Init_write_IRV: accessed-variable=LeftFrontWhlDir_Init_write_IRV
        FsftCSVR_e_LeftRearWhlDir
          written-local-variables:
            access WV_LeftRearWhlDir_FA_Init_write_IRV: accessed-variable=LeftRearWhlDir_FA_Init_write_IRV
            access WV_LeftRearWhlDir_Init_write_IRV: accessed-variable=LeftRearWhlDir_Init_write_IRV
        FsftCSVR_e_OutSpdPolarity
          written-local-variables:
            access WV_OutSpdPolarityFA_initVal_write_IRV: accessed-variable=OutSpdPolarityFA_initVal_write_IRV
        FsftCSVR_e_RightFrontWhlDir
          written-local-variables:
            access WV_RightFrontWhlDir_FA_Init_write_IRV: accessed-variable=RightFrontWhlDir_FA_Init_write_IRV
            access WV_RightFrontWhlDir_Init_write_IRV: accessed-variable=RightFrontWhlDir_Init_write_IRV
        FsftCSVR_e_RightRearWhlDir
          written-local-variables:
            access WV_RightRearWhlDir_FA_Init_write_IRV: accessed-variable=RightRearWhlDir_FA_Init_write_IRV
            access WV_RightRearWhlDir_Init_write_IRV: accessed-variable=RightRearWhlDir_Init_write_IRV
        FsftCSVR_n_LeftFrontWhl
          written-local-variables:
            access WV_LeftFrontWhlFA_Init_write_IRV: accessed-variable=LeftFrontWhlFA_Init_write_IRV
        FsftCSVR_n_LeftRearWhl
          written-local-variables:
            access WV_LeftRearWhlFA_Init_write_IRV: accessed-variable=LeftRearWhlFA_Init_write_IRV
        FsftCSVR_n_Nturb
          written-local-variables:
            access WV_NturbFA_Init_write_IRV: accessed-variable=NturbFA_Init_write_IRV
        FsftCSVR_n_RightFrontWhl
          written-local-variables:
            access WV_RightFrontWhlFA_Init_write_IRV: accessed-variable=RightFrontWhlFA_Init_write_IRV
        FsftCSVR_n_RightRearWhl
          written-local-variables:
            access WV_RightRearWhlFA_Init_write_IRV: accessed-variable=RightRearWhlFA_Init_write_IRV
        FsftCSVR_n_ST2InpSpd
          written-local-variables:
            access WV_ST2InpSpdFA_Init_write_IRV: accessed-variable=ST2InpSpdFA_Init_write_IRV
        FsftCSVR_n_TOSSnsrSpdRaw
          written-local-variables:
            access WV_TOSSnsrSpdRawFA_Init_write_IRV: accessed-variable=TOSSnsrSpdRawFA_Init_write_IRV
        FsftCSVR_v_CanSigVehSpd
          written-local-variables:
            access WV_CanVehSpdFA_Init_write_IRV: accessed-variable=CanVehSpdFA_Init_write_IRV
        FsftCSVR_v_CanSigVehSpd_CANC2
          written-local-variables:
            access WV_CanVehSpdFA_CANC2_Init_write_IRV: accessed-variable=CanVehSpdFA_CANC2_Init_write_IRV
        FsftCSVR_v_RefVehSpd
          written-local-variables:
            access WV_RefVehSpdFA_Init_write_IRV: accessed-variable=RefVehSpdFA_Init_write_IRV
        PokeCSVR_b_VehSpdVSOSigFailSts
          written-local-variables:
            access WV_VehSpdVSOSigFailSts_Init_write_IRV: accessed-variable=VehSpdVSOSigFailSts_Init_write_IRV
        PokeCSVR_b_VehSpdVSOSigFailSts_CANC2
          written-local-variables:
            access WV_VeCSVI_b_VehSpdVSOSigFailStsSR_CANC2_Init_write_IRV: accessed-variable=VeCSVI_b_VehSpdVSOSigFailStsSR_CANC2_Init_write_IRV
            access WV_VehSpdVSOSigFailSts_CANC2_Init_write_IRV: accessed-variable=VehSpdVSOSigFailSts_CANC2_Init_write_IRV
        PokeCSVR_b_WheelSensorFailStsLHF
          written-local-variables:
            access WV_WheelSensorFailStsLHF_Init_write_IRV: accessed-variable=WheelSensorFailStsLHF_Init_write_IRV
        PokeCSVR_b_WheelSensorFailStsLHR
          written-local-variables:
            access WV_WheelSensorFailStsLHR_Init_write_IRV: accessed-variable=WheelSensorFailStsLHR_Init_write_IRV
        PokeCSVR_b_WheelSensorFailStsRHF
          written-local-variables:
            access WV_WheelSensorFailStsRHF_Init_write_IRV: accessed-variable=WheelSensorFailStsRHF_Init_write_IRV
        PokeCSVR_b_WheelSensorFailStsRHR
          written-local-variables:
            access WV_WheelSensorFailStsRHR_Init_write_IRV: accessed-variable=WheelSensorFailStsRHR_Init_write_IRV
        PokeCSVR_e_LeftFrontWhlDir
          written-local-variables:
            access WV_LeftFrontWhlDir_FA_Init_write_IRV: accessed-variable=LeftFrontWhlDir_FA_Init_write_IRV
            access WV_LeftFrontWhlDir_Init_write_IRV: accessed-variable=LeftFrontWhlDir_Init_write_IRV
        PokeCSVR_e_LeftRearWhlDir
          written-local-variables:
            access WV_LeftRearWhlDir_FA_Init_write_IRV: accessed-variable=LeftRearWhlDir_FA_Init_write_IRV
            access WV_LeftRearWhlDir_Init_write_IRV: accessed-variable=LeftRearWhlDir_Init_write_IRV
        PokeCSVR_e_OutSpdPolarity
          written-local-variables:
            access WV_OutSpdPolarityFA_initVal_write_IRV: accessed-variable=OutSpdPolarityFA_initVal_write_IRV
            access WV_OutSpdPolarity_initVal_write_IRV: accessed-variable=OutSpdPolarity_initVal_write_IRV
        PokeCSVR_e_RightFrontWhlDir
          written-local-variables:
            access WV_RightFrontWhlDir_FA_Init_write_IRV: accessed-variable=RightFrontWhlDir_FA_Init_write_IRV
            access WV_RightFrontWhlDir_Init_write_IRV: accessed-variable=RightFrontWhlDir_Init_write_IRV
        PokeCSVR_e_RightRearWhlDir
          written-local-variables:
            access WV_RightRearWhlDir_FA_Init_write_IRV: accessed-variable=RightRearWhlDir_FA_Init_write_IRV
            access WV_RightRearWhlDir_Init_write_IRV: accessed-variable=RightRearWhlDir_Init_write_IRV
        PokeCSVR_e_THA_STAT
          written-local-variables:
            access WV_THA_STATFA_Init_write_IRV: accessed-variable=THA_STATFA_Init_write_IRV
            access WV_THA_STAT_Init_write_IRV: accessed-variable=THA_STAT_Init_write_IRV
        PokeCSVR_e_THA_SpdLim
          written-local-variables:
            access WV_THA_SpdLimFA_Init_write_IRV: accessed-variable=THA_SpdLimFA_Init_write_IRV
            access WV_THA_SpdLim_Init_write_IRV: accessed-variable=THA_SpdLim_Init_write_IRV
        PokeCSVR_e_TRSC_STAT
          written-local-variables:
            access WV_TRSC_STATFA_Init_write_IRV: accessed-variable=TRSC_STATFA_Init_write_IRV
            access WV_TRSC_STAT_Init_write_IRV: accessed-variable=TRSC_STAT_Init_write_IRV
        PokeCSVR_e_TRSC_SpdLimReq
          written-local-variables:
            access WV_TRSC_SpdLimReqFA_Init_write_IRV: accessed-variable=TRSC_SpdLimReqFA_Init_write_IRV
            access WV_TRSC_SpdLimReq_Init_write_IRV: accessed-variable=TRSC_SpdLimReq_Init_write_IRV
        PokeCSVR_n_LeftFrontWhl
          written-local-variables:
            access WV_LeftFrontWhlFA_Init_write_IRV: accessed-variable=LeftFrontWhlFA_Init_write_IRV
            access WV_LeftFrontWhl_Init_write_IRV: accessed-variable=LeftFrontWhl_Init_write_IRV
        PokeCSVR_n_LeftRearWhl
          written-local-variables:
            access WV_LeftRearWhlFA_Init_write_IRV: accessed-variable=LeftRearWhlFA_Init_write_IRV
            access WV_LeftRearWhl_Init_write_IRV: accessed-variable=LeftRearWhl_Init_write_IRV
        PokeCSVR_n_Nturb
          written-local-variables:
            access WV_NturbFA_Init_write_IRV: accessed-variable=NturbFA_Init_write_IRV
            access WV_Nturb_Init_write_IRV: accessed-variable=Nturb_Init_write_IRV
        PokeCSVR_n_RightFrontWhl
          written-local-variables:
            access WV_RightFrontWhlFA_Init_write_IRV: accessed-variable=RightFrontWhlFA_Init_write_IRV
            access WV_RightFrontWhl_Init_write_IRV: accessed-variable=RightFrontWhl_Init_write_IRV
        PokeCSVR_n_RightRearWhl
          written-local-variables:
            access WV_RightRearWhlFA_Init_write_IRV: accessed-variable=RightRearWhlFA_Init_write_IRV
            access WV_RightRearWhl_Init_write_IRV: accessed-variable=RightRearWhl_Init_write_IRV
        PokeCSVR_n_ST2InpSpd
          written-local-variables:
            access WV_ST2InpSpdFA_Init_write_IRV: accessed-variable=ST2InpSpdFA_Init_write_IRV
            access WV_ST2InpSpd_Init_write_IRV: accessed-variable=ST2InpSpd_Init_write_IRV
        PokeCSVR_n_TOSSnsrSpdRaw
          written-local-variables:
            access WV_TOSSnsrSpdRawFA_Init_write_IRV: accessed-variable=TOSSnsrSpdRawFA_Init_write_IRV
            access WV_TOS_SnsrSpdRaw_Init_write_IRV: accessed-variable=TOS_SnsrSpdRaw_Init_write_IRV
        PokeCSVR_v_CanSigVehSpd
          written-local-variables:
            access WV_CanVehSpdFA_Init_write_IRV: accessed-variable=CanVehSpdFA_Init_write_IRV
            access WV_CanVehSpd_Init_write_IRV: accessed-variable=CanVehSpd_Init_write_IRV
        PokeCSVR_v_CanSigVehSpd_CANC2
          written-local-variables:
            access WV_CanVehSpdFA_CANC2_Init_write_IRV: accessed-variable=CanVehSpdFA_CANC2_Init_write_IRV
            access WV_VeCSVI_b_CanSigVehSpdSR_CANC2_Init_write_IRV: accessed-variable=VeCSVI_b_CanSigVehSpdSR_CANC2_Init_write_IRV
            access WV_CanVehSpd_CANC2_Init_write_IRV: accessed-variable=CanVehSpd_CANC2_Init_write_IRV
        PokeCSVR_v_RefVehSpd
          written-local-variables:
            access WV_RefVehSpdFA_Init_write_IRV: accessed-variable=RefVehSpdFA_Init_write_IRV
            access WV_RefVehSpd_Init_write_IRV: accessed-variable=RefVehSpd_Init_write_IRV
      variation point proxy Variant_CSVR_2: category=CONDITION, condition-access=0
